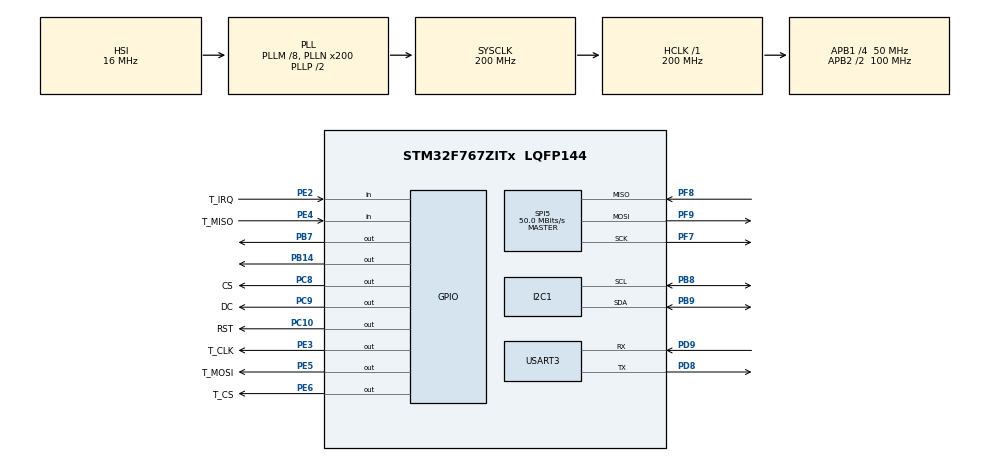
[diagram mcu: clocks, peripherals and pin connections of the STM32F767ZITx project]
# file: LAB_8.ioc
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CORTEX_M7.ART_ACCELERATOR_ENABLE=1
CORTEX_M7.CPU_DCache=Enabled
CORTEX_M7.CPU_ICache=Enabled
CORTEX_M7.MPU_Control=__NULL
CORTEX_M7.PREFETCH_ENABLE=1
CORTEX_M7.default_mode_Activation=1
I2C1.Timing=0x00C0EAFF
Mcu.Family=STM32F7
Mcu.Name=STM32F767ZITx
Mcu.Package=LQFP144
NVIC.PriorityGroup=NVIC_PRIORITYGROUP_2
PB14.Signal=GPIO_Output
PB7.Signal=GPIO_Output
PB8.Mode=I2C
PB8.Signal=I2C1_SCL
PB9.Mode=I2C
PB9.Signal=I2C1_SDA
PC10.GPIO_Label=RST
PC10.GPIO_Speed=GPIO_SPEED_FREQ_VERY_HIGH
PC10.Signal=GPIO_Output
PC8.GPIO_Label=CS
PC8.GPIO_Speed=GPIO_SPEED_FREQ_VERY_HIGH
PC8.PinState=GPIO_PIN_RESET
PC8.Signal=GPIO_Output
PC9.GPIO_Label=DC
PC9.GPIO_Speed=GPIO_SPEED_FREQ_VERY_HIGH
PC9.Signal=GPIO_Output
PD8.Mode=Asynchronous
PD8.Signal=USART3_TX
PD9.Mode=Asynchronous
PD9.Signal=USART3_RX
PE2.GPIO_Label=T_IRQ
PE2.Signal=GPIO_Input
PE3.GPIO_Label=T_CLK
PE3.GPIO_Speed=GPIO_SPEED_FREQ_VERY_HIGH
PE3.Signal=GPIO_Output
PE4.GPIO_Label=T_MISO
PE4.Signal=GPIO_Input
PE5.GPIO_Label=T_MOSI
PE5.GPIO_Speed=GPIO_SPEED_FREQ_VERY_HIGH
PE5.Signal=GPIO_Output
PE6.GPIO_Label=T_CS
PE6.GPIO_Speed=GPIO_SPEED_FREQ_VERY_HIGH
PE6.Signal=GPIO_Output
PF7.Mode=Full_Duplex_Master
PF7.Signal=SPI5_SCK
PF8.Mode=Full_Duplex_Master
PF8.Signal=SPI5_MISO
PF9.Mode=Full_Duplex_Master
PF9.Signal=SPI5_MOSI
PH0/OSC_IN.Mode=HSE-External-Oscillator
PH0/OSC_IN.Signal=RCC_OSC_IN
PH1/OSC_OUT.Mode=HSE-External-Oscillator
PH1/OSC_OUT.Signal=RCC_OSC_OUT
ProjectManager.HeapSize=0x200
ProjectManager.StackSize=0x400
ProjectManager.TargetToolchain=STM32CubeIDE
RCC.AHBFreq_Value=200000000
RCC.APB1CLKDivider=RCC_HCLK_DIV4
RCC.APB1Freq_Value=50000000
RCC.APB1TimFreq_Value=100000000
RCC.APB2CLKDivider=RCC_HCLK_DIV2
RCC.APB2Freq_Value=100000000
RCC.APB2TimFreq_Value=200000000
RCC.CortexFreq_Value=200000000
RCC.HCLKFreq_Value=200000000
RCC.HSE_VALUE=8000000
RCC.HSI_VALUE=16000000
RCC.LSE_VALUE=32768
RCC.PLLM=8
RCC.PLLN=200
RCC.PLLQ=9
RCC.SYSCLKFreq_VALUE=200000000
RCC.SYSCLKSource=RCC_SYSCLKSOURCE_PLLCLK
RCC.USBFreq_Value=44444444.44444445
RCC.VCOOutputFreq_Value=400000000
SPI5.CalculateBaudRate=50.0 MBits/s
SPI5.DataSize=SPI_DATASIZE_8BIT
SPI5.Direction=SPI_DIRECTION_2LINES
SPI5.Mode=SPI_MODE_MASTER
SPI5.NSSPMode=SPI_NSS_PULSE_DISABLE
SPI5.VirtualType=VM_MASTER
TIM1.ClockDivision=TIM_CLOCKDIVISION_DIV2
TIM1.Period=0
TIM1.Prescaler=10000
USART3.VirtualMode-Asynchronous=VM_ASYNC
VP_RNG_VS_RNG.Mode=RNG_Activate
VP_TIM1_VS_ClockSourceINT.Mode=Internal
board=custom

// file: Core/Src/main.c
/* USER CODE BEGIN Header */
/**
  ******************************************************************************
  * @file           : main.c
  * @brief          : Main program body
  ******************************************************************************
  * @attention
  *
  * Copyright (c) 2026 STMicroelectronics.
  * All rights reserved.
  *
  * This software is licensed under terms that can be found in the LICENSE file
  * in the root directory of this software component.
  * If no LICENSE file comes with this software, it is provided AS-IS.
  *
  ******************************************************************************
  */
/* USER CODE END Header */
#include "main.h"
#include "i2c.h"
#include "rng.h"
#include "spi.h"
#include "tim.h"
#include "usart.h"
#include "gpio.h"

/* USER CODE BEGIN Includes */
#include "stdio.h"
#include "string.h"
#include "ILI9341_GFX.h"
#include "ILI9341_STM32_Driver.h"
#include "ILI9341_Touchscreen.h"
/* USER CODE END Includes */

/* USER CODE BEGIN PD */
#define LD2_Pin GPIO_PIN_7
#define LD3_Pin GPIO_PIN_14

#define LIGHT_RED    0xFDB5
#define LIGHT_GREEN  0xC718
#define LIGHT_BLUE   0xAEDF
/* USER CODE END PD */

/* USER CODE BEGIN PV */
float h=30.0, t=40.0;
uint8_t step;
HAL_StatusTypeDef status;
uint8_t r_percent = 0, g_percent = 0, b_percent = 0;
const uint16_t profile[] = {
		0xff,0xff,0xff,0xff,0xff,0xff,0xff,0xff,0xff,0xff,0xff,0xff,0xff,0xff,0xff,0xff,0xff,0xff,0xff,0xff,0xff,0xff,0xff,0xff,0xff,0xff,0xff,0xff,0xff,0xff,0xff,0xff,0xff,0xff,0xff,0xff,0xff,0xff,0xff,0xff,0xff,0xff,0xff,0xff,0xff,0xff,0xff,0xff,0xff,0xff,0xff,0xff,0xff,0xff,0xff,0xff,0xff,0xff,0xff,0xff,0xff,0xff,0xff,0xff,0xff,0xff,0xff,0xff,0xff,0xff,0xff,0xff,0xff,0xff,0xff,0xff,0xff,0xff,0xff,0xff,0xff,0xff,0xff,0xff,0xff,0xff,0xff,0xff,0xff,0xff
		,0xff,0xff,0xff,0xff,0xff,0xff,0xff,0xff,0xff,0xff,0xff,0xff,0xff,0xff,0xff,0xff,0xff,0xff,0xff,0xff,0xff,0xff,0xff,0xff,0xff,0xff,0xff,0xff,0xff,0xff,0xff,0xff,0xff,0xff,0xff,0xff,0xff,0xff,0xff,0xff,0xff,0xff,0xff,0xff,0xff,0xff,0xff,0xff,0xff,0xff,0xff,0xff,0xff,0xff,0xff,0xff,0xff,0xff,0xff,0xff,0xff,0xff,0xff,0xff,0xff,0xff,0xff,0xff,0xff,0xff,0xff,0xff,0xff,0xff,0xff,0xff,0xff,0xff,0xff,0xff,0xff,0xff,0xff,0xff,0xff,0xff,0xff,0xff,0xff,0xff
		,0xff,0xff,0xff,0xff,0xff,0xff,0xff,0xff,0xff,0xff,0xff,0xff,0xff,0xff,0xff,0xff,0xff,0xff,0xff,0xff,0xff,0xff,0xff,0xff,0xff,0xff,0xff,0xff,0xff,0xff,0xff,0xff,0xff,0xff,0xff,0xff,0xff,0xff,0xff,0xff,0xff,0xff,0xff,0xff,0xff,0xff,0xff,0xff,0xff,0xff,0xff,0xff,0xff,0xff,0xff,0xff,0xff,0xff,0xff,0xff,0xff,0xff,0xff,0xff,0xff,0xff,0xff,0xff,0xff,0xff,0xff,0xff,0xff,0xff,0xff,0xff,0xff,0xff,0xff,0xff,0xff,0xff,0xff,0xff,0xff,0xff,0xff,0xff,0xff,0xff
		,0xff,0xff,0xff,0xff,0xff,0xff,0xff,0xff,0xff,0xff,0xff,0xff,0xff,0xff,0xff,0xff,0xff,0xff,0xff,0xff,0xff,0xff,0xff,0xff,0xff,0xff,0xff,0xff,0xff,0xff,0xff,0xff,0xff,0xff,0xff,0xff,0xff,0xff,0xff,0xff,0xff,0xff,0xff,0xff,0xff,0xff,0xff,0xff,0xff,0xff,0xff,0xff,0xff,0xff,0xff,0xff,0xff,0xff,0xff,0xff,0xff,0xff,0xff,0xff,0xff,0xff,0xff,0xff,0xff,0xff,0xff,0xff,0xff,0xff,0xff,0xff,0xff,0xff,0xff,0xff,0xff,0xff,0xff,0xff,0xff,0xff,0xff,0xff,0xff,0xff
		,0xff,0xff,0xff,0xff,0xff,0xff,0xff,0xff,0xff,0xff,0xff,0xff,0xff,0xff,0xff,0xff,0xff,0xff,0xff,0xff,0xff,0xff,0xff,0xff,0xff,0xff,0xff,0xff,0xff,0xff,0xff,0xff,0xff,0xff,0xff,0xff,0xff,0xff,0xff,0xff,0xff,0xff,0xff,0xff,0xff,0xff,0xff,0xff,0xff,0xff,0xff,0xff,0xff,0xff,0xff,0xff,0xff,0xff,0xff,0xff,0xff,0xff,0xff,0xff,0xff,0xff,0xff,0xff,0xff,0xff,0xff,0xff,0xff,0xff,0xff,0xff,0xff,0xff,0xff,0xff,0xff,0xff,0xff,0xff,0xff,0xff,0xff,0xff,0xff,0xff
		,0xff,0xff,0xff,0xff,0xff,0xff,0xff,0xff,0xff,0xff,0xff,0xff,0xff,0xff,0xff,0xff,0xff,0xff,0xff,0xff,0xff,0xff,0xff,0xff,0xff,0xff,0xff,0xff,0xff,0xff,0xff,0xff,0xff,0xff,0xff,0xff,0xff,0xff,0xff,0xff,0xff,0xff,0xff,0xff,0xff,0xff,0xff,0xff,0xff,0xff,0xff,0xff,0xff,0xff,0xff,0xff,0xff,0xff,0xff,0xff,0xff,0xff,0xff,0xff,0xff,0xff,0xff,0xff,0xff,0xff,0xff,0xff,0xff,0xff,0xff,0xff,0xff,0xff,0xff,0xff,0xff,0xff,0xff,0xff,0xff,0xff,0xff,0xff,0xff,0xff
		,0xff,0xff,0xff,0xff,0xff,0xff,0xff,0xff,0xff,0xff,0xff,0xff,0xff,0xff,0xff,0xff,0xff,0xff,0xff,0xff,0xff,0xff,0xff,0xff,0xff,0xff,0xff,0xff,0xff,0xff,0xff,0xff,0xff,0xff,0xff,0xff,0xff,0xff,0xff,0xff,0xff,0xff,0xff,0xff,0xff,0xff,0xff,0xff,0xff,0xff,0xff,0xff,0xff,0xff,0xff,0xff,0xff,0xff,0xff,0xff,0xff,0xff,0xff,0xff,0xff,0xff,0xff,0xff,0xff,0xff,0xff,0xff,0xff,0xff,0xff,0xff,0xff,0xff,0xff,0xff,0xff,0xff,0xff,0xff,0xff,0xff,0xff,0xff,0xff,0xff
		,0xff,0xff,0xff,0xff,0xff,0xff,0xff,0xff,0xff,0xff,0xff,0xff,0xff,0xff,0xff,0xff,0xff,0xff,0xff,0xff,0xff,0xff,0xff,0xff,0xff,0xff,0xff,0xff,0xff,0xff,0xff,0xff,0xff,0xff,0xff,0xff,0xff,0xff,0xff,0xff,0xff,0xff,0xff,0xff,0xff,0xff,0xff,0xff,0xff,0xff,0xff,0xff,0xff,0xff,0xff,0xff,0xff,0xff,0xff,0xff,0xff,0xff,0xff,0xff,0xff,0xff,0xff,0xff,0xff,0xff,0xff,0xff,0xff,0xff,0xff,0xff,0xff,0xff,0xff,0xff,0xff,0xff,0xff,0xff,0xff,0xff,0xff,0xff,0xff,0xff
		,0xff,0xff,0xff,0xff,0xff,0xff,0xff,0xff,0xff,0xff,0xff,0xff,0xff,0xff,0xff,0xff,0xff,0xff,0xff,0xff,0xff,0xff,0xff,0xff,0xff,0xff,0xff,0xff,0xff,0xff,0xff,0xff,0xff,0xff,0xff,0xff,0xff,0xff,0xff,0xff,0xff,0xff,0xff,0xff,0xdb,0xdb,0xff,0xff,0xff,0xff,0xff,0xdb,0xff,0xff,0xff,0xff,0xff,0xff,0xff,0xff,0xff,0xff,0xff,0xff,0xff,0xff,0xff,0xff,0xff,0xff,0xff,0xff,0xff,0xff,0xff,0xff,0xff,0xff,0xff,0xff,0xff,0xff,0xff,0xff,0xff,0xff,0xff,0xff,0xff,0xff
		,0xff,0xff,0xff,0xff,0xff,0xff,0xff,0xff,0xff,0xff,0xff,0xff,0xff,0xff,0xff,0xff,0xff,0xff,0xff,0xff,0xff,0xff,0xff,0xff,0xff,0xff,0xff,0xff,0xff,0xff,0xff,0xff,0xff,0xff,0xff,0xff,0xff,0xff,0xff,0xff,0xdb,0x92,0x49,0x25,0x25,0x49,0x49,0x6d,0x49,0x24,0x25,0x24,0x49,0xff,0xff,0xff,0xff,0xff,0xff,0xff,0xff,0xff,0xff,0xff,0xff,0xff,0xff,0xff,0xff,0xff,0xff,0xff,0xff,0xff,0xff,0xff,0xff,0xff,0xff,0xff,0xff,0xff,0xff,0xff,0xff,0xff,0xff,0xff,0xff,0xff
		,0xff,0xff,0xff,0xff,0xff,0xff,0xff,0xff,0xff,0xff,0xff,0xff,0xff,0xff,0xff,0xff,0xff,0xff,0xff,0xff,0xff,0xff,0xff,0xff,0xff,0xff,0xff,0xff,0xff,0xff,0xff,0xff,0xff,0xff,0xff,0xff,0xff,0xb6,0x72,0x49,0x24,0x00,0x00,0x00,0x00,0x00,0x00,0x00,0x00,0x00,0x00,0x00,0x00,0x49,0xdb,0xff,0xff,0xff,0xff,0xff,0xff,0xff,0xff,0xff,0xff,0xff,0xff,0xff,0xff,0xff,0xff,0xff,0xff,0xff,0xff,0xff,0xff,0xff,0xff,0xff,0xff,0xff,0xff,0xff,0xff,0xff,0xff,0xff,0xff,0xff
		,0xff,0xff,0xff,0xff,0xff,0xff,0xff,0xff,0xff,0xff,0xff,0xff,0xff,0xff,0xff,0xff,0xff,0xff,0xff,0xff,0xff,0xff,0xff,0xff,0xff,0xff,0xff,0xff,0xff,0xff,0xff,0xff,0xff,0xff,0xff,0xb6,0x29,0x00,0x04,0x00,0x00,0x00,0x00,0x00,0x00,0x00,0x00,0x00,0x00,0x00,0x00,0x00,0x00,0x00,0x6d,0xdb,0xff,0xff,0xff,0xff,0xff,0xff,0xff,0xff,0xff,0xff,0xff,0xff,0xff,0xff,0xff,0xff,0xff,0xff,0xff,0xff,0xff,0xff,0xff,0xff,0xff,0xff,0xff,0xff,0xff,0xff,0xff,0xff,0xff,0xff
		,0xff,0xff,0xff,0xff,0xff,0xff,0xff,0xff,0xff,0xff,0xff,0xff,0xff,0xff,0xff,0xff,0xff,0xff,0xff,0xff,0xff,0xff,0xff,0xff,0xff,0xff,0xff,0xff,0xff,0xff,0xff,0xff,0xff,0xb6,0x49,0x24,0x00,0x00,0x00,0x00,0x00,0x00,0x00,0x00,0x00,0x00,0x00,0x00,0x00,0x00,0x00,0x00,0x00,0x00,0x00,0x49,0x49,0x6e,0xb6,0xff,0xff,0xff,0xff,0xff,0xff,0xff,0xff,0xff,0xff,0xff,0xff,0xff,0xff,0xff,0xff,0xff,0xff,0xff,0xff,0xff,0xff,0xff,0xff,0xff,0xff,0xff,0xff,0xff,0xff,0xff
		,0xff,0xff,0xff,0xff,0xff,0xff,0xff,0xff,0xff,0xff,0xff,0xff,0xff,0xff,0xff,0xff,0xff,0xff,0xff,0xff,0xff,0xff,0xff,0xff,0xff,0xff,0xff,0xff,0xff,0xff,0xff,0xff,0x6d,0x24,0x00,0x00,0x00,0x00,0x00,0x00,0x00,0x00,0x00,0x00,0x00,0x00,0x00,0x00,0x00,0x00,0x00,0x00,0x00,0x00,0x00,0x00,0x00,0x00,0x25,0x49,0xdb,0xff,0xff,0xff,0xff,0xff,0xff,0xff,0xff,0xff,0xff,0xff,0xff,0xff,0xff,0xff,0xff,0xff,0xff,0xff,0xff,0xff,0xff,0xff,0xff,0xff,0xff,0xff,0xff,0xff
		,0xff,0xff,0xff,0xff,0xff,0xff,0xff,0xff,0xff,0xff,0xff,0xff,0xff,0xff,0xff,0xff,0xff,0xff,0xff,0xff,0xff,0xff,0xff,0xff,0xff,0xff,0xff,0xff,0xff,0xff,0xff,0x92,0x24,0x00,0x00,0x00,0x00,0x00,0x00,0x00,0x00,0x00,0x00,0x00,0x00,0x00,0x00,0x00,0x00,0x00,0x00,0x00,0x00,0x00,0x00,0x00,0x00,0x00,0x00,0x04,0x24,0x92,0xff,0xff,0xff,0xff,0xff,0xff,0xff,0xff,0xff,0xff,0xff,0xff,0xff,0xff,0xff,0xff,0xff,0xff,0xff,0xff,0xff,0xff,0xff,0xff,0xff,0xff,0xff,0xff
		,0xff,0xff,0xff,0xff,0xff,0xff,0xff,0xff,0xff,0xff,0xff,0xff,0xff,0xff,0xff,0xff,0xff,0xff,0xff,0xff,0xff,0xff,0xff,0xff,0xff,0xff,0xff,0xff,0xff,0xdb,0x49,0x24,0x00,0x00,0x00,0x00,0x00,0x00,0x00,0x00,0x00,0x00,0x00,0x00,0x00,0x00,0x00,0x00,0x00,0x00,0x00,0x00,0x00,0x00,0x00,0x00,0x00,0x00,0x00,0x00,0x00,0x04,0x49,0xdb,0xff,0xff,0xff,0xff,0xff,0xff,0xff,0xff,0xff,0xff,0xff,0xff,0xff,0xff,0xff,0xff,0xff,0xff,0xff,0xff,0xff,0xff,0xff,0xff,0xff,0xff
		,0xff,0xff,0xff,0xff,0xff,0xff,0xff,0xff,0xff,0xff,0xff,0xff,0xff,0xff,0xff,0xff,0xff,0xff,0xff,0xff,0xff,0xff,0xff,0xff,0xff,0xff,0xff,0xff,0xb6,0x29,0x24,0x00,0x00,0x00,0x00,0x00,0x00,0x00,0x00,0x00,0x00,0x00,0x00,0x00,0x00,0x00,0x00,0x00,0x00,0x00,0x00,0x00,0x00,0x00,0x00,0x00,0x00,0x00,0x00,0x00,0x00,0x00,0x04,0x49,0xbb,0xff,0xff,0xff,0xff,0xff,0xff,0xff,0xff,0xff,0xff,0xff,0xff,0xff,0xff,0xff,0xff,0xff,0xff,0xff,0xff,0xff,0xff,0xff,0xff,0xff
		,0xff,0xff,0xff,0xff,0xff,0xff,0xff,0xff,0xff,0xff,0xff,0xff,0xff,0xff,0xff,0xff,0xff,0xff,0xff,0xff,0xff,0xff,0xff,0xff,0xff,0xff,0xff,0xb7,0x25,0x24,0x25,0x00,0x00,0x00,0x00,0x00,0x00,0x00,0x00,0x00,0x00,0x00,0x00,0x00,0x00,0x00,0x00,0x00,0x00,0x00,0x00,0x00,0x00,0x00,0x00,0x00,0x00,0x00,0x00,0x00,0x00,0x00,0x00,0x24,0x6e,0xb7,0xff,0xff,0xff,0xff,0xff,0xff,0xff,0xff,0xff,0xff,0xff,0xff,0xff,0xff,0xff,0xff,0xff,0xff,0xff,0xff,0xff,0xff,0xff,0xff
		,0xff,0xff,0xff,0xff,0xff,0xff,0xff,0xff,0xff,0xff,0xff,0xff,0xff,0xff,0xff,0xff,0xff,0xff,0xff,0xff,0xff,0xff,0xff,0xff,0xff,0xff,0xff,0x49,0x24,0x25,0x00,0x00,0x00,0x00,0x00,0x24,0x24,0x00,0x00,0x00,0x00,0x00,0x00,0x00,0x00,0x00,0x00,0x00,0x00,0x00,0x00,0x00,0x00,0x00,0x00,0x00,0x00,0x00,0x00,0x00,0x00,0x00,0x00,0x00,0x24,0x29,0xdb,0xff,0xff,0xff,0xff,0xff,0xff,0xff,0xff,0xff,0xff,0xff,0xff,0xff,0xff,0xff,0xff,0xff,0xff,0xff,0xff,0xff,0xff,0xff
		,0xff,0xff,0xff,0xff,0xff,0xff,0xff,0xff,0xff,0xff,0xff,0xff,0xff,0xff,0xff,0xff,0xff,0xff,0xff,0xff,0xff,0xff,0xff,0xff,0xff,0xff,0x92,0x24,0x04,0x00,0x00,0x00,0x00,0x00,0x24,0x24,0x04,0x00,0x00,0x00,0x00,0x00,0x00,0x00,0x00,0x00,0x00,0x00,0x00,0x00,0x00,0x00,0x00,0x00,0x00,0x00,0x00,0x00,0x00,0x00,0x00,0x00,0x00,0x00,0x00,0x00,0x25,0xb7,0xff,0xff,0xff,0xff,0xff,0xff,0xff,0xff,0xff,0xff,0xff,0xff,0xff,0xff,0xff,0xff,0xff,0xff,0xff,0xff,0xff,0xff
		,0xff,0xff,0xff,0xff,0xff,0xff,0xff,0xff,0xff,0xff,0xff,0xff,0xff,0xff,0xff,0xff,0xff,0xff,0xff,0xff,0xff,0xff,0xff,0xff,0xff,0xb6,0x25,0x00,0x00,0x24,0x24,0x00,0x00,0x24,0x25,0x24,0x04,0x24,0x25,0x24,0x04,0x00,0x00,0x00,0x00,0x00,0x00,0x00,0x00,0x00,0x00,0x00,0x00,0x00,0x00,0x00,0x00,0x00,0x00,0x00,0x00,0x00,0x00,0x00,0x00,0x00,0x00,0x24,0xdb,0xff,0xff,0xff,0xff,0xff,0xff,0xff,0xff,0xff,0xff,0xff,0xff,0xff,0xff,0xff,0xff,0xff,0xff,0xff,0xff,0xff
		,0xff,0xff,0xff,0xff,0xff,0xff,0xff,0xff,0xff,0xff,0xff,0xff,0xff,0xff,0xff,0xff,0xff,0xff,0xff,0xff,0xff,0xff,0xff,0xff,0xdb,0x29,0x00,0x00,0x25,0x25,0x25,0x24,0x25,0x25,0x25,0x25,0x25,0x25,0x25,0x25,0x00,0x00,0x00,0x00,0x00,0x00,0x00,0x00,0x04,0x00,0x00,0x00,0x00,0x00,0x00,0x00,0x00,0x00,0x00,0x00,0x00,0x00,0x00,0x00,0x00,0x00,0x00,0x00,0x49,0xff,0xff,0xff,0xff,0xff,0xff,0xff,0xff,0xff,0xff,0xff,0xff,0xff,0xff,0xff,0xff,0xff,0xff,0xff,0xff,0xff
		,0xff,0xff,0xff,0xff,0xff,0xff,0xff,0xff,0xff,0xff,0xff,0xff,0xff,0xff,0xff,0xff,0xff,0xff,0xff,0xff,0xff,0xff,0xff,0xff,0x6d,0x04,0x00,0x04,0x25,0x25,0x25,0x04,0x04,0x04,0x25,0x25,0x04,0x00,0x00,0x04,0x24,0x25,0x00,0x00,0x00,0x00,0x00,0x00,0x00,0x04,0x00,0x00,0x00,0x00,0x00,0x00,0x00,0x00,0x00,0x00,0x00,0x00,0x00,0x00,0x00,0x00,0x00,0x00,0x00,0x6e,0xff,0xff,0xff,0xff,0xff,0xff,0xff,0xff,0xff,0xff,0xff,0xff,0xff,0xff,0xff,0xff,0xff,0xff,0xff,0xff
		,0xff,0xff,0xff,0xff,0xff,0xff,0xff,0xff,0xff,0xff,0xff,0xff,0xff,0xff,0xff,0xff,0xff,0xff,0xff,0xff,0xff,0xff,0xff,0x92,0x04,0x00,0x04,0x04,0x00,0x00,0x00,0x00,0x00,0x24,0x00,0x00,0x00,0x04,0x24,0x24,0x25,0x25,0x24,0x00,0x00,0x00,0x00,0x00,0x00,0x00,0x00,0x00,0x00,0x20,0x00,0x00,0x00,0x00,0x00,0x00,0x00,0x00,0x00,0x00,0x00,0x00,0x00,0x04,0x00,0x20,0xdb,0xff,0xff,0xff,0xff,0xff,0xff,0xff,0xff,0xff,0xff,0xff,0xff,0xff,0xff,0xff,0xff,0xff,0xff,0xff
		,0xff,0xff,0xff,0xff,0xff,0xff,0xff,0xff,0xff,0xff,0xff,0xff,0xff,0xff,0xff,0xff,0xff,0xff,0xff,0xff,0xff,0xff,0xdf,0x29,0x00,0x00,0x00,0x00,0x00,0x00,0x00,0x00,0x00,0x00,0x00,0x24,0x04,0x24,0x24,0x24,0x00,0x24,0x24,0x00,0x00,0x00,0x00,0x00,0x04,0x00,0x00,0x24,0x24,0x00,0x00,0x00,0x00,0x00,0x00,0x00,0x00,0x00,0x00,0x00,0x00,0x00,0x04,0x24,0x04,0x00,0x49,0xff,0xff,0xff,0xff,0xff,0xff,0xff,0xff,0xff,0xff,0xff,0xff,0xff,0xff,0xff,0xff,0xff,0xff,0xff
		,0xff,0xff,0xff,0xff,0xff,0xff,0xff,0xff,0xff,0xff,0xff,0xff,0xff,0xff,0xff,0xff,0xff,0xff,0xff,0xff,0xff,0xff,0x92,0x00,0x00,0x00,0x00,0x00,0x00,0x00,0x00,0x00,0x00,0x00,0x04,0x25,0x24,0x25,0x25,0x24,0x04,0x00,0x00,0x00,0x00,0x00,0x00,0x24,0x00,0x24,0x24,0x00,0x00,0x00,0x00,0x00,0x00,0x00,0x00,0x00,0x00,0x00,0x00,0x00,0x00,0x00,0x25,0x04,0x00,0x00,0x24,0xdb,0xff,0xff,0xff,0xff,0xff,0xff,0xff,0xff,0xff,0xff,0xff,0xff,0xff,0xff,0xff,0xff,0xff,0xff
		,0xff,0xff,0xff,0xff,0xff,0xff,0xff,0xff,0xff,0xff,0xff,0xff,0xff,0xff,0xff,0xff,0xff,0xff,0xff,0xff,0xff,0xdb,0x25,0x00,0x04,0x00,0x00,0x00,0x00,0x00,0x00,0x00,0x00,0x04,0x25,0x24,0x00,0x24,0x25,0x25,0x25,0x04,0x04,0x00,0x00,0x00,0x24,0x25,0x25,0x24,0x00,0x00,0x00,0x00,0x00,0x20,0x00,0x00,0x00,0x00,0x00,0x00,0x00,0x00,0x00,0x00,0x25,0x04,0x00,0x00,0x00,0x92,0xff,0xff,0xff,0xff,0xff,0xff,0xff,0xff,0xff,0xff,0xff,0xff,0xff,0xff,0xff,0xff,0xff,0xff
		,0xff,0xff,0xff,0xff,0xff,0xff,0xff,0xff,0xff,0xff,0xff,0xff,0xff,0xff,0xff,0xff,0xff,0xff,0xff,0xff,0xff,0x6e,0x00,0x00,0x04,0x00,0x00,0x00,0x00,0x00,0x00,0x00,0x04,0x24,0x04,0x00,0x00,0x04,0x24,0x25,0x25,0x24,0x04,0x04,0x00,0x24,0x25,0x00,0x00,0x00,0x00,0x24,0x00,0x00,0x20,0x00,0x00,0x00,0x00,0x00,0x00,0x00,0x04,0x00,0x24,0x00,0x04,0x00,0x00,0x00,0x00,0x49,0xff,0xff,0xff,0xff,0xff,0xff,0xff,0xff,0xff,0xff,0xff,0xff,0xff,0xff,0xff,0xff,0xff,0xff
		,0xff,0xff,0xff,0xff,0xff,0xff,0xff,0xff,0xff,0xff,0xff,0xff,0xff,0xff,0xff,0xff,0xff,0xff,0xff,0xff,0xdb,0x24,0x00,0x00,0x00,0x00,0x00,0x00,0x00,0x00,0x00,0x00,0x00,0x00,0x20,0x00,0x00,0x00,0x24,0x25,0x25,0x25,0x25,0x25,0x25,0x25,0x25,0x20,0x20,0x20,0x00,0x24,0x24,0x24,0x20,0x20,0x00,0x00,0x00,0x00,0x00,0x00,0x24,0x00,0x04,0x04,0x04,0x04,0x00,0x25,0x04,0x24,0xdb,0xff,0xff,0xff,0xff,0xff,0xff,0xff,0xff,0xff,0xff,0xff,0xff,0xff,0xff,0xff,0xff,0xff
		,0xff,0xff,0xff,0xff,0xff,0xff,0xff,0xff,0xff,0xff,0xff,0xff,0xff,0xff,0xff,0xff,0xff,0xff,0xff,0xff,0xb6,0x00,0x00,0x00,0x00,0x00,0x00,0x00,0x00,0x00,0x00,0x00,0x00,0x00,0x00,0x20,0x00,0x00,0x00,0x00,0x25,0x25,0x25,0x20,0x25,0x25,0x45,0x24,0x24,0x24,0x20,0x24,0x24,0x00,0x20,0x00,0x00,0x20,0x00,0x00,0x00,0x00,0x04,0x00,0x00,0x00,0x05,0x00,0x00,0x00,0x25,0x00,0xb7,0xff,0xff,0xff,0xff,0xff,0xff,0xff,0xff,0xff,0xff,0xff,0xff,0xff,0xff,0xff,0xff,0xff
		,0xff,0xff,0xff,0xff,0xff,0xff,0xff,0xff,0xff,0xff,0xff,0xff,0xff,0xff,0xff,0xff,0xff,0xff,0xff,0xff,0x92,0x00,0x00,0x00,0x00,0x00,0x00,0x00,0x00,0x00,0x00,0x00,0x00,0x20,0x20,0x24,0x00,0x00,0x00,0x00,0x20,0x24,0x24,0x25,0x45,0x69,0x69,0x45,0x45,0x24,0x24,0x24,0x20,0x20,0x20,0x00,0x00,0x20,0x20,0x20,0x24,0x00,0x00,0x04,0x00,0x00,0x05,0x00,0x00,0x00,0x04,0x05,0x92,0xff,0xff,0xff,0xff,0xff,0xff,0xff,0xff,0xff,0xff,0xff,0xff,0xff,0xff,0xff,0xff,0xff
		,0xff,0xff,0xff,0xff,0xff,0xff,0xff,0xff,0xff,0xff,0xff,0xff,0xff,0xff,0xff,0xff,0xff,0xff,0xff,0xff,0x6e,0x00,0x00,0x00,0x00,0x00,0x00,0x00,0x00,0x00,0x00,0x20,0x20,0x20,0x24,0x20,0x00,0x00,0x24,0x24,0x44,0x25,0x25,0x44,0x69,0x69,0x45,0x45,0x45,0x45,0x24,0x24,0x24,0x24,0x20,0x00,0x20,0x24,0x44,0x24,0x45,0x20,0x00,0x00,0x04,0x05,0x25,0x00,0x00,0x00,0x00,0x25,0x6e,0xff,0xff,0xff,0xff,0xff,0xff,0xff,0xff,0xff,0xff,0xff,0xff,0xff,0xff,0xff,0xff,0xff
		,0xff,0xff,0xff,0xff,0xff,0xff,0xff,0xff,0xff,0xff,0xff,0xff,0xff,0xff,0xff,0xff,0xff,0xff,0xff,0xff,0x6d,0x00,0x00,0x00,0x00,0x00,0x00,0x00,0x00,0x00,0x20,0x24,0x20,0x24,0x20,0x00,0x24,0x45,0x65,0x69,0x69,0x45,0x69,0x69,0x69,0x45,0x45,0x69,0x45,0x45,0x25,0x45,0x25,0x24,0x20,0x20,0x24,0x44,0x44,0x25,0x69,0x24,0x00,0x00,0x04,0x25,0x25,0x00,0x00,0x04,0x00,0x25,0x92,0xff,0xff,0xff,0xff,0xff,0xff,0xff,0xff,0xff,0xff,0xff,0xff,0xff,0xff,0xff,0xff,0xff
		,0xff,0xff,0xff,0xff,0xff,0xff,0xff,0xff,0xff,0xff,0xff,0xff,0xff,0xff,0xff,0xff,0xff,0xff,0xff,0xff,0x49,0x00,0x00,0x00,0x00,0x00,0x00,0x00,0x20,0x00,0x44,0x20,0x20,0x20,0x00,0x24,0x45,0x69,0x8d,0x89,0x44,0x89,0x8d,0x89,0x69,0x69,0x69,0x8d,0x69,0x49,0x25,0x25,0x25,0x24,0x20,0x24,0x45,0x45,0x45,0x45,0x69,0x45,0x20,0x00,0x04,0x04,0x25,0x00,0x00,0x04,0x00,0x05,0x72,0xff,0xff,0xff,0xff,0xff,0xff,0xff,0xff,0xff,0xff,0xff,0xff,0xff,0xff,0xff,0xff,0xff
		,0xff,0xff,0xff,0xff,0xff,0xff,0xff,0xff,0xff,0xff,0xff,0xff,0xff,0xff,0xff,0xff,0xff,0xff,0xff,0xff,0x24,0x00,0x00,0x00,0x00,0x00,0x00,0x20,0x20,0x44,0x24,0x00,0x20,0x00,0x24,0x45,0x69,0x8d,0x89,0x89,0x8d,0xad,0x8d,0x8d,0xad,0x8d,0x8d,0x89,0x69,0x45,0x24,0x45,0x45,0x24,0x24,0x44,0x69,0x69,0x69,0x69,0x69,0x45,0x20,0x00,0x25,0x00,0x25,0x00,0x00,0x04,0x04,0x25,0x6e,0xff,0xff,0xff,0xff,0xff,0xff,0xff,0xff,0xff,0xff,0xff,0xff,0xff,0xff,0xff,0xff,0xff
		,0xff,0xff,0xff,0xff,0xff,0xff,0xff,0xff,0xff,0xff,0xff,0xff,0xff,0xff,0xff,0xff,0xff,0xff,0xff,0xff,0x24,0x00,0x00,0x00,0x00,0x00,0x00,0x44,0x20,0x44,0x00,0x44,0x20,0x24,0x45,0x69,0x89,0x8d,0x8d,0xb2,0xae,0xb2,0xb2,0xae,0xb2,0xb2,0xae,0x89,0x45,0x45,0x69,0x45,0x45,0x45,0x45,0x45,0x89,0x89,0x69,0x69,0x69,0x69,0x24,0x00,0x25,0x00,0x25,0x04,0x00,0x05,0x04,0x25,0x6e,0xff,0xff,0xff,0xff,0xff,0xff,0xff,0xff,0xff,0xff,0xff,0xff,0xff,0xff,0xff,0xff,0xff
		,0xff,0xff,0xff,0xff,0xff,0xff,0xff,0xff,0xff,0xff,0xff,0xff,0xff,0xff,0xff,0xff,0xff,0xff,0xff,0xff,0x24,0x00,0x00,0x00,0x00,0x00,0x00,0x44,0x24,0x24,0x24,0x44,0x24,0x44,0x65,0x89,0xad,0xad,0xb2,0xd2,0xd2,0xd2,0xd2,0xb2,0xb2,0xb2,0x8d,0x69,0x69,0x45,0x69,0x45,0x69,0x69,0x69,0x89,0x89,0x8d,0x69,0x69,0x89,0x89,0x44,0x20,0x25,0x04,0x04,0x05,0x00,0x05,0x25,0x25,0x6e,0xff,0xff,0xff,0xff,0xff,0xff,0xff,0xff,0xff,0xff,0xff,0xff,0xff,0xff,0xff,0xff,0xff
		,0xff,0xff,0xff,0xff,0xff,0xff,0xff,0xff,0xff,0xff,0xff,0xff,0xff,0xff,0xff,0xff,0xff,0xff,0xff,0xff,0x25,0x00,0x00,0x00,0x00,0x00,0x20,0x69,0x44,0x20,0x44,0x44,0x69,0x65,0x89,0xad,0xae,0xb2,0xd2,0xd2,0xd6,0xd2,0xd2,0xb2,0xd2,0xad,0x8d,0xad,0x45,0x69,0x69,0x89,0x69,0x69,0x69,0x8d,0x89,0x8d,0x69,0x89,0x8d,0x89,0x44,0x24,0x24,0x00,0x04,0x25,0x05,0x04,0x04,0x05,0x92,0xff,0xff,0xff,0xff,0xff,0xff,0xff,0xff,0xff,0xff,0xff,0xff,0xff,0xff,0xff,0xff,0xff
		,0xff,0xff,0xff,0xff,0xff,0xff,0xff,0xff,0xff,0xff,0xff,0xff,0xff,0xff,0xff,0xff,0xff,0xff,0xff,0xff,0x49,0x00,0x00,0x00,0x00,0x00,0x20,0x65,0x69,0x44,0x65,0x69,0x69,0x89,0xad,0xb2,0xd2,0xd2,0xd6,0xd6,0xd6,0xd6,0xd2,0xd2,0xb2,0xae,0xb2,0x8d,0x44,0x69,0x89,0x8d,0x89,0x89,0x8d,0xad,0x8d,0x8d,0x69,0x89,0x8d,0x8d,0x69,0x24,0x00,0x00,0x04,0x25,0x25,0x00,0x04,0x00,0x92,0xff,0xff,0xff,0xff,0xff,0xff,0xff,0xff,0xff,0xff,0xff,0xff,0xff,0xff,0xff,0xff,0xff
		,0xff,0xff,0xff,0xff,0xff,0xff,0xff,0xff,0xff,0xff,0xff,0xff,0xff,0xff,0xff,0xff,0xff,0xff,0xff,0xff,0x6d,0x00,0x00,0x00,0x00,0x00,0x24,0x69,0x89,0x44,0x89,0x8d,0x69,0xad,0xb2,0xd2,0xd2,0xd6,0xd6,0xd6,0xd6,0xd6,0xd6,0xd6,0xae,0xd2,0xd2,0x69,0x69,0x8d,0x8d,0x89,0x89,0x8d,0xae,0xad,0x8d,0x89,0x89,0x8d,0xad,0xad,0x65,0x24,0x00,0x00,0x04,0x25,0x25,0x00,0x00,0x00,0xb6,0xff,0xff,0xff,0xff,0xff,0xff,0xff,0xff,0xff,0xff,0xff,0xff,0xff,0xff,0xff,0xff,0xff
		,0xff,0xff,0xff,0xff,0xff,0xff,0xff,0xff,0xff,0xff,0xff,0xff,0xff,0xff,0xff,0xff,0xff,0xff,0xff,0xff,0x92,0x00,0x00,0x00,0x00,0x00,0x44,0x89,0x89,0x44,0xad,0x69,0x8d,0xb2,0xd2,0xd6,0xd6,0xd6,0xd6,0xd6,0xd6,0xd6,0xd6,0xd2,0xb2,0xd2,0xb2,0x69,0xae,0xb2,0xae,0x89,0x8e,0xb2,0xae,0x8e,0x8d,0x69,0x8d,0xad,0xad,0xad,0x69,0x44,0x20,0x00,0x24,0x04,0x04,0x00,0x00,0x24,0xff,0xff,0xff,0xff,0xff,0xff,0xff,0xff,0xff,0xff,0xff,0xff,0xff,0xff,0xff,0xff,0xff,0xff
		,0xff,0xff,0xff,0xff,0xff,0xff,0xff,0xff,0xff,0xff,0xff,0xff,0xff,0xff,0xff,0xff,0xff,0xff,0xff,0xff,0xff,0x49,0x00,0x00,0x00,0x24,0x44,0x89,0x8d,0x69,0x8d,0x45,0x8d,0xb2,0xb2,0xd6,0xd6,0xd6,0xd6,0xd6,0xd6,0xd6,0xd6,0xd2,0xd2,0xd2,0x8d,0xad,0xb2,0xae,0xae,0x8e,0x8e,0x8e,0x8d,0x69,0x69,0x45,0x69,0xad,0xad,0xad,0x89,0x69,0x44,0x20,0x24,0x24,0x00,0x00,0x00,0x6d,0xff,0xff,0xff,0xff,0xff,0xff,0xff,0xff,0xff,0xff,0xff,0xff,0xff,0xff,0xff,0xff,0xff,0xff
		,0xff,0xff,0xff,0xff,0xff,0xff,0xff,0xff,0xff,0xff,0xff,0xff,0xff,0xff,0xff,0xff,0xff,0xff,0xff,0xff,0xff,0xdb,0x25,0x00,0x20,0x24,0x69,0x8d,0xad,0x69,0x69,0x45,0x69,0x8d,0x8e,0xb2,0xb2,0xd6,0xd6,0xd6,0xd6,0xd6,0xd6,0xd2,0xd6,0xd2,0xae,0xb2,0xb2,0xae,0x8d,0x69,0x49,0x49,0x49,0x69,0x69,0x45,0x45,0x69,0xad,0xad,0x8d,0x89,0x45,0x24,0x24,0x20,0x00,0x00,0x00,0xb7,0xff,0xff,0xff,0xff,0xff,0xff,0xff,0xff,0xff,0xff,0xff,0xff,0xff,0xff,0xff,0xff,0xff,0xff
		,0xff,0xff,0xff,0xff,0xff,0xff,0xff,0xff,0xff,0xff,0xff,0xff,0xff,0xff,0xff,0xff,0xff,0xff,0xff,0xff,0xff,0xff,0x72,0x00,0x20,0x44,0x8d,0xad,0xad,0x49,0x44,0x45,0x69,0x69,0x69,0x69,0x69,0x8e,0xb2,0xd2,0xd6,0xd6,0xd6,0xd6,0xd6,0xd6,0xb2,0xb2,0xae,0x89,0x45,0x45,0x69,0x69,0x8e,0xb2,0xae,0x8d,0x8d,0x69,0x89,0xad,0xad,0xad,0x69,0x44,0x24,0x00,0x00,0x00,0x49,0xff,0xff,0xff,0xff,0xff,0xff,0xff,0xff,0xff,0xff,0xff,0xff,0xff,0xff,0xff,0xff,0xff,0xff,0xff
		,0xff,0xff,0xff,0xff,0xff,0xff,0xff,0xff,0xff,0xff,0xff,0xff,0xff,0xff,0xff,0xff,0xff,0xff,0xff,0xff,0xff,0xff,0xdb,0x24,0x24,0x45,0x8d,0xad,0x89,0x69,0x8d,0x8e,0xb2,0xb2,0x8e,0x69,0x69,0x69,0x69,0x8d,0xb2,0xd2,0xd6,0xd6,0xd6,0xd6,0xb2,0xb2,0xae,0x8d,0x8d,0x8e,0xb2,0xd6,0xd6,0xd6,0xd2,0xb2,0xb2,0xae,0x8d,0xad,0xad,0xad,0x8d,0x45,0x24,0x20,0x00,0x04,0x92,0xff,0xff,0xff,0xff,0xff,0xff,0xff,0xff,0xff,0xff,0xff,0xff,0xff,0xff,0xff,0xff,0xff,0xff,0xff
		,0xff,0xff,0xff,0xff,0xff,0xff,0xff,0xff,0xff,0xff,0xff,0xff,0xff,0xff,0xff,0xff,0xff,0xff,0xff,0xff,0xff,0xff,0xff,0x49,0x24,0x45,0xad,0xad,0xad,0xad,0xb2,0xb2,0xd6,0xd6,0xd6,0xd6,0xb2,0xae,0x8d,0x8d,0xae,0xb2,0xd6,0xd6,0xd6,0xd6,0xd2,0xae,0xae,0xb2,0xb2,0xd2,0xd6,0xd6,0xd7,0xd6,0xd6,0xd2,0xd2,0xb2,0xae,0xb2,0xad,0xad,0xad,0x69,0x24,0x20,0x00,0x24,0xdb,0xff,0xff,0xff,0xff,0xff,0xff,0xff,0xff,0xff,0xff,0xff,0xff,0xff,0xff,0xff,0xff,0xff,0xff,0xff
		,0xff,0xff,0xff,0xff,0xff,0xff,0xff,0xff,0xff,0xff,0xff,0xff,0xff,0xff,0xff,0xff,0xff,0xff,0xff,0xff,0xff,0xff,0xff,0x6d,0x24,0x45,0xad,0xad,0xb2,0xb2,0xb2,0xd2,0xd6,0xd6,0xd6,0xd6,0xd6,0xd2,0xb2,0xb2,0xb2,0xb2,0xd2,0xd6,0xd6,0xd6,0xd2,0xb2,0xb2,0xb2,0xd2,0xd2,0xd2,0xd6,0xd6,0xd2,0xd2,0xd2,0xd2,0xb2,0xb2,0xb2,0xb2,0xad,0xad,0x69,0x24,0x24,0x00,0x45,0xb2,0xd6,0xdb,0xff,0xff,0xff,0xff,0xff,0xff,0xff,0xff,0xff,0xff,0xff,0xff,0xff,0xff,0xff,0xff,0xff
		,0xff,0xff,0xff,0xff,0xff,0xff,0xff,0xff,0xff,0xff,0xff,0xff,0xff,0xff,0xff,0xff,0xff,0xff,0xff,0xff,0xfb,0xd2,0xb2,0x8d,0x24,0x49,0xad,0xb1,0xb2,0xb2,0xb2,0xb2,0xd2,0xd2,0xd2,0xd2,0xb2,0xb2,0xb2,0xb2,0xb2,0xd2,0xd6,0xd6,0xd6,0xd6,0xd2,0xd2,0xb2,0xd2,0xb2,0x8d,0x69,0x49,0x45,0x45,0x69,0x8d,0xad,0xb2,0xb2,0xd2,0xb2,0xb1,0xad,0x69,0x24,0x44,0x45,0xd2,0xb2,0xad,0xd2,0xd7,0xff,0xff,0xff,0xff,0xff,0xff,0xff,0xff,0xff,0xff,0xff,0xff,0xff,0xff,0xff,0xff
		,0xff,0xff,0xff,0xff,0xff,0xff,0xff,0xff,0xff,0xff,0xff,0xff,0xff,0xff,0xff,0xff,0xff,0xff,0xff,0xff,0xd2,0x89,0xad,0xad,0x44,0x69,0xad,0xb1,0xb2,0xb2,0xad,0x89,0x45,0x45,0x25,0x24,0x25,0x49,0xae,0xd2,0xd2,0xd2,0xd6,0xd6,0xf7,0xd6,0xd2,0xd2,0xd2,0xd2,0xae,0x8e,0x49,0x00,0x00,0x69,0x69,0x44,0x89,0xad,0xb2,0xd2,0xd2,0xb2,0xad,0x8d,0x44,0x69,0xd2,0xd2,0xd2,0xd2,0xad,0xd2,0xfb,0xff,0xff,0xff,0xff,0xff,0xff,0xff,0xff,0xff,0xff,0xff,0xff,0xff,0xff,0xff
		,0xff,0xff,0xff,0xff,0xff,0xff,0xff,0xff,0xff,0xff,0xff,0xff,0xff,0xff,0xff,0xff,0xff,0xff,0xff,0xff,0xd2,0x89,0xad,0xb2,0x69,0x69,0xad,0xb2,0xd2,0xb2,0x8d,0x65,0x65,0xb2,0x69,0x00,0x20,0x8e,0x69,0xd2,0xd2,0xd2,0xd6,0xf6,0xf6,0xd6,0xd2,0xd2,0xd6,0xd6,0xae,0xae,0x8e,0x49,0x69,0xae,0x8d,0xad,0xae,0xb2,0xd2,0xd2,0xd2,0xb2,0xad,0xad,0x65,0xb2,0xd2,0xd2,0xd2,0xd2,0xd2,0xad,0xd7,0xff,0xff,0xff,0xff,0xff,0xff,0xff,0xff,0xff,0xff,0xff,0xff,0xff,0xff,0xff
		,0xff,0xff,0xff,0xff,0xff,0xff,0xff,0xff,0xff,0xff,0xff,0xff,0xff,0xff,0xff,0xff,0xff,0xff,0xff,0xff,0xd2,0xad,0xb2,0xb2,0x89,0x89,0xad,0xd2,0xd2,0xd2,0xd2,0xb2,0xb2,0xb2,0xb2,0x8e,0xae,0xb2,0xb2,0xd6,0xd6,0xd6,0xd6,0xf6,0xf6,0xd6,0xd2,0xd2,0xd6,0xd6,0xd6,0xd6,0xd2,0xd2,0xd2,0xd2,0xd2,0xd2,0xd6,0xd6,0xd6,0xd6,0xd2,0xb2,0xad,0xad,0x69,0xad,0xb2,0xd2,0xd6,0xd6,0xd2,0xad,0xd6,0xff,0xff,0xff,0xff,0xff,0xff,0xff,0xff,0xff,0xff,0xff,0xff,0xff,0xff,0xff
		,0xff,0xff,0xff,0xff,0xff,0xff,0xff,0xff,0xff,0xff,0xff,0xff,0xff,0xff,0xff,0xff,0xff,0xff,0xff,0xff,0xd2,0xae,0xd2,0xd2,0x89,0x8d,0xad,0xd2,0xd2,0xd6,0xd6,0xd6,0xd6,0xd6,0xd6,0xd2,0xd2,0xd6,0xd6,0xd6,0xd6,0xd6,0xd6,0xf6,0xf6,0xd6,0xd2,0xd2,0xd6,0xd6,0xd7,0xd6,0xd6,0xd6,0xd6,0xd6,0xd6,0xd6,0xd6,0xd6,0xd6,0xd6,0xd2,0xd2,0xb1,0xad,0x89,0xad,0xd6,0xd6,0xd6,0xd6,0xd2,0xae,0xd6,0xff,0xff,0xff,0xff,0xff,0xff,0xff,0xff,0xff,0xff,0xff,0xff,0xff,0xff,0xff
		,0xff,0xff,0xff,0xff,0xff,0xff,0xff,0xff,0xff,0xff,0xff,0xff,0xff,0xff,0xff,0xff,0xff,0xff,0xff,0xff,0xd2,0xd2,0xd2,0xd2,0x8d,0xad,0xb1,0xd2,0xd2,0xd6,0xd6,0xd6,0xd6,0xd6,0xd6,0xd6,0xd6,0xd6,0xd6,0xd6,0xd6,0xd6,0xd6,0xf6,0xfb,0xd6,0xd6,0xd2,0xd6,0xd6,0xd6,0xd6,0xd6,0xd6,0xd7,0xd7,0xd6,0xd6,0xd6,0xd6,0xd6,0xd6,0xd2,0xd2,0xb2,0xad,0x8d,0x8d,0xae,0xd2,0xd2,0xd6,0xd2,0xd2,0xfb,0xff,0xff,0xff,0xff,0xff,0xff,0xff,0xff,0xff,0xff,0xff,0xff,0xff,0xff,0xff
		,0xff,0xff,0xff,0xff,0xff,0xff,0xff,0xff,0xff,0xff,0xff,0xff,0xff,0xff,0xff,0xff,0xff,0xff,0xff,0xff,0xd6,0xd2,0xd2,0xad,0x89,0xad,0xb2,0xd2,0xd6,0xd6,0xd6,0xd6,0xd7,0xd7,0xd6,0xd6,0xd6,0xd6,0xd6,0xd6,0xd6,0xd6,0xd6,0xf6,0xfb,0xf6,0xd2,0xd2,0xd2,0xd6,0xd6,0xd7,0xd7,0xd7,0xd7,0xd7,0xd7,0xd6,0xd6,0xd6,0xd6,0xd6,0xd2,0xd2,0xb2,0xad,0x8d,0xae,0xae,0xd2,0xd2,0xd6,0xd2,0xd2,0xff,0xff,0xff,0xff,0xff,0xff,0xff,0xff,0xff,0xff,0xff,0xff,0xff,0xff,0xff,0xff
		,0xff,0xff,0xff,0xff,0xff,0xff,0xff,0xff,0xff,0xff,0xff,0xff,0xff,0xff,0xff,0xff,0xff,0xff,0xff,0xff,0xd6,0xd2,0xb2,0xad,0x89,0xad,0xb2,0xd2,0xd2,0xd6,0xd6,0xd7,0xdb,0xd7,0xd7,0xd6,0xf7,0xf7,0xf6,0xd6,0xd6,0xd6,0xd6,0xf6,0xfb,0xd6,0xd6,0xd2,0xd2,0xd6,0xd6,0xd7,0xfb,0xd7,0xfb,0xdb,0xd7,0xd6,0xd6,0xd6,0xd6,0xd6,0xd2,0xd2,0xb2,0xad,0x8d,0xd2,0xd2,0xd2,0xd2,0xd2,0xb2,0xd6,0xff,0xff,0xff,0xff,0xff,0xff,0xff,0xff,0xff,0xff,0xff,0xff,0xff,0xff,0xff,0xff
		,0xff,0xff,0xff,0xff,0xff,0xff,0xff,0xff,0xff,0xff,0xff,0xff,0xff,0xff,0xff,0xff,0xff,0xff,0xff,0xff,0xd7,0xd2,0xae,0x89,0x89,0xad,0xb2,0xd2,0xd6,0xd6,0xd6,0xd7,0xfb,0xfb,0xf7,0xf7,0xf7,0xf7,0xd6,0xd6,0xd6,0xd6,0xd6,0xf7,0xfb,0xd6,0xd6,0xd2,0xd2,0xd6,0xd6,0xf7,0xfb,0xfb,0xfb,0xfb,0xd7,0xd6,0xd6,0xd6,0xd6,0xd2,0xd2,0xd2,0xb2,0xad,0x8d,0xd2,0xd2,0xd2,0xd2,0xd2,0xb2,0xfb,0xff,0xff,0xff,0xff,0xff,0xff,0xff,0xff,0xff,0xff,0xff,0xff,0xff,0xff,0xff,0xff
		,0xff,0xff,0xff,0xff,0xff,0xff,0xff,0xff,0xff,0xff,0xff,0xff,0xff,0xff,0xff,0xff,0xff,0xff,0xff,0xff,0xfb,0xd2,0xb2,0x89,0x89,0xad,0xb1,0xd2,0xd6,0xd6,0xd6,0xd6,0xd7,0xfb,0xfb,0xfb,0xfb,0xf7,0xd6,0xd6,0xd2,0xd6,0xd6,0xfb,0xfb,0xd6,0xd6,0xd2,0xd2,0xd6,0xd6,0xd7,0xfb,0xfb,0xfb,0xfb,0xd7,0xd6,0xd6,0xd6,0xd6,0xd2,0xd2,0xd2,0xb1,0xad,0xad,0xd2,0xd2,0xd2,0xd6,0xd2,0xd2,0xff,0xff,0xff,0xff,0xff,0xff,0xff,0xff,0xff,0xff,0xff,0xff,0xff,0xff,0xff,0xff,0xff
		,0xff,0xff,0xff,0xff,0xff,0xff,0xff,0xff,0xff,0xff,0xff,0xff,0xff,0xff,0xff,0xff,0xff,0xff,0xff,0xff,0xff,0xd2,0xd2,0xa9,0xad,0xad,0xb2,0xd2,0xd6,0xd6,0xd6,0xd6,0xfb,0xfb,0xfb,0xfb,0xfb,0xf7,0xd6,0xd6,0xd6,0xd6,0xd6,0xfb,0xfb,0xd7,0xd6,0xd6,0xd2,0xd2,0xd6,0xd7,0xfb,0xfb,0xfb,0xfb,0xd7,0xd6,0xd6,0xd6,0xd6,0xd6,0xd2,0xb2,0xad,0x8d,0xad,0xd2,0xd2,0xd2,0xd6,0xd2,0xdb,0xff,0xff,0xff,0xff,0xff,0xff,0xff,0xff,0xff,0xff,0xff,0xff,0xff,0xff,0xff,0xff,0xff
		,0xff,0xff,0xff,0xff,0xff,0xff,0xff,0xff,0xff,0xff,0xff,0xff,0xff,0xff,0xff,0xff,0xff,0xff,0xff,0xff,0xff,0xd2,0xd2,0xad,0xad,0xad,0xad,0xd2,0xd6,0xd6,0xd6,0xd6,0xd7,0xfb,0xfb,0xfb,0xf7,0xf7,0xd6,0xd6,0xd6,0xd6,0xd2,0xd6,0xd6,0xd6,0xd2,0xd6,0xd6,0xd2,0xd6,0xd6,0xf7,0xfb,0xfb,0xd7,0xd7,0xd6,0xd6,0xd6,0xd6,0xd2,0xd2,0xb2,0xad,0x8d,0xad,0xd6,0xd2,0xd6,0xd6,0xd6,0xff,0xff,0xff,0xff,0xff,0xff,0xff,0xff,0xff,0xff,0xff,0xff,0xff,0xff,0xff,0xff,0xff,0xff
		,0xff,0xff,0xff,0xff,0xff,0xff,0xff,0xff,0xff,0xff,0xff,0xff,0xff,0xff,0xff,0xff,0xff,0xff,0xff,0xff,0xff,0xd7,0xd2,0xd2,0xb2,0xad,0xad,0xb2,0xd2,0xd6,0xd6,0xd6,0xd7,0xfb,0xfb,0xfb,0xf7,0xf7,0xd6,0xd2,0xd6,0xd2,0xb2,0xd2,0xd2,0xb2,0xad,0xb2,0xd2,0xd2,0xd6,0xd6,0xd6,0xd7,0xd7,0xd7,0xd6,0xd6,0xd6,0xd6,0xd6,0xd2,0xb2,0xb2,0xad,0x8d,0xb2,0xd6,0xd6,0xd6,0xd6,0xfb,0xff,0xff,0xff,0xff,0xff,0xff,0xff,0xff,0xff,0xff,0xff,0xff,0xff,0xff,0xff,0xff,0xff,0xff
		,0xff,0xff,0xff,0xff,0xff,0xff,0xff,0xff,0xff,0xff,0xff,0xff,0xff,0xff,0xff,0xff,0xff,0xff,0xff,0xff,0xff,0xff,0xd2,0xd2,0xd2,0xad,0xad,0xb2,0xd2,0xd6,0xd6,0xd6,0xd7,0xd7,0xd7,0xf7,0xf7,0xd7,0xd6,0xd2,0xb2,0x65,0x44,0x8d,0x8d,0x8d,0x65,0x44,0xad,0xb2,0xd6,0xd6,0xd6,0xd7,0xd7,0xd7,0xd6,0xd6,0xd6,0xd6,0xd6,0xd2,0xb2,0xb2,0xad,0x8d,0xd2,0xd6,0xd6,0xd6,0xd6,0xff,0xff,0xff,0xff,0xff,0xff,0xff,0xff,0xff,0xff,0xff,0xff,0xff,0xff,0xff,0xff,0xff,0xff,0xff
		,0xff,0xff,0xff,0xff,0xff,0xff,0xff,0xff,0xff,0xff,0xff,0xff,0xff,0xff,0xff,0xff,0xff,0xff,0xff,0xff,0xff,0xff,0xd6,0xd2,0xd2,0xad,0xad,0xad,0xd2,0xd2,0xd6,0xd6,0xd6,0xd6,0xd6,0xd7,0xf6,0xd6,0xd6,0xd2,0xad,0xb2,0xb2,0xb2,0xad,0xb2,0xb2,0xb2,0xad,0xb2,0xd6,0xd6,0xd6,0xd6,0xd7,0xd6,0xd6,0xd6,0xd6,0xd6,0xd2,0xd2,0xb2,0xad,0xad,0x8d,0xd6,0xd6,0xd6,0xd6,0xff,0xff,0xff,0xff,0xff,0xff,0xff,0xff,0xff,0xff,0xff,0xff,0xff,0xff,0xff,0xff,0xff,0xff,0xff,0xff
		,0xff,0xff,0xff,0xff,0xff,0xff,0xff,0xff,0xff,0xff,0xff,0xff,0xff,0xff,0xff,0xff,0xff,0xff,0xff,0xff,0xff,0xff,0xfb,0xd2,0xd2,0xd2,0x8d,0xad,0xb2,0xd2,0xd6,0xd6,0xd6,0xd6,0xd6,0xd6,0xd6,0xf6,0xd6,0xd6,0xd2,0xd2,0xd2,0xd6,0xd2,0xd2,0xd2,0xd2,0xd2,0xd6,0xd6,0xd6,0xd6,0xd6,0xd6,0xd6,0xd6,0xd6,0xd6,0xd2,0xd2,0xb2,0xb2,0xad,0x8d,0xad,0xd6,0xd6,0xd6,0xfb,0xff,0xff,0xff,0xff,0xff,0xff,0xff,0xff,0xff,0xff,0xff,0xff,0xff,0xff,0xff,0xff,0xff,0xff,0xff,0xff
		,0xff,0xff,0xff,0xff,0xff,0xff,0xff,0xff,0xff,0xff,0xff,0xff,0xff,0xff,0xff,0xff,0xff,0xff,0xff,0xff,0xff,0xff,0xff,0xd6,0xb2,0xd2,0x8d,0xad,0xb2,0xd2,0xd2,0xd6,0xd6,0xd6,0xd6,0xd6,0xd6,0xd6,0xd6,0xd6,0xd6,0xd6,0xd6,0xd6,0xd6,0xd6,0xd6,0xd6,0xd6,0xd6,0xd6,0xd6,0xd6,0xd6,0xd6,0xd6,0xd6,0xd6,0xd6,0xd2,0xd2,0xb2,0xb2,0xad,0x8d,0xb2,0xd6,0xfb,0xff,0xff,0xff,0xff,0xff,0xff,0xff,0xff,0xff,0xff,0xff,0xff,0xff,0xff,0xff,0xff,0xff,0xff,0xff,0xff,0xff,0xff
		,0xff,0xff,0xff,0xff,0xff,0xff,0xff,0xff,0xff,0xff,0xff,0xff,0xff,0xff,0xff,0xff,0xff,0xff,0xff,0xff,0xff,0xff,0xff,0xff,0xff,0xdb,0xb2,0x8d,0xae,0xb2,0xd2,0xd2,0xd6,0xd6,0xd6,0xd6,0xd6,0xd6,0xd6,0xd6,0xd6,0xd6,0xd6,0xd6,0xd6,0xd6,0xd6,0xd6,0xd6,0xd6,0xd6,0xd6,0xd6,0xd6,0xd6,0xd6,0xd6,0xd2,0xd2,0xd2,0xb2,0xb2,0xad,0xad,0x8d,0xff,0xff,0xff,0xff,0xff,0xff,0xff,0xff,0xff,0xff,0xff,0xff,0xff,0xff,0xff,0xff,0xff,0xff,0xff,0xff,0xff,0xff,0xff,0xff,0xff
		,0xff,0xff,0xff,0xff,0xff,0xff,0xff,0xff,0xff,0xff,0xff,0xff,0xff,0xff,0xff,0xff,0xff,0xff,0xff,0xff,0xff,0xff,0xff,0xff,0xff,0xff,0xff,0xad,0xae,0xb2,0xb2,0xd2,0xd2,0xd6,0xd6,0xd6,0xd6,0xd6,0xd6,0xd6,0xd6,0xd6,0xd2,0xd2,0xd6,0xd2,0xd2,0xd6,0xd6,0xd2,0xd2,0xd6,0xd2,0xd2,0xd6,0xd6,0xd6,0xd2,0xd2,0xd2,0xb2,0xb2,0xad,0x8d,0xd6,0xff,0xff,0xff,0xff,0xff,0xff,0xff,0xff,0xff,0xff,0xff,0xff,0xff,0xff,0xff,0xff,0xff,0xff,0xff,0xff,0xff,0xff,0xff,0xff,0xff
		,0xff,0xff,0xff,0xff,0xff,0xff,0xff,0xff,0xff,0xff,0xff,0xff,0xff,0xff,0xff,0xff,0xff,0xff,0xff,0xff,0xff,0xff,0xff,0xff,0xff,0xff,0xff,0xb6,0xad,0xb2,0xb2,0xd2,0xd2,0xd2,0xd2,0xd6,0xd2,0xd2,0xd2,0xd2,0xd2,0xae,0xce,0xae,0xce,0xae,0xae,0xae,0xd2,0xd2,0xb2,0xb2,0xd2,0xd2,0xd2,0xd2,0xd2,0xd2,0xd2,0xb2,0xb2,0xb2,0xad,0x8d,0xff,0xff,0xff,0xff,0xff,0xff,0xff,0xff,0xff,0xff,0xff,0xff,0xff,0xff,0xff,0xff,0xff,0xff,0xff,0xff,0xff,0xff,0xff,0xff,0xff,0xff
		,0xff,0xff,0xff,0xff,0xff,0xff,0xff,0xff,0xff,0xff,0xff,0xff,0xff,0xff,0xff,0xff,0xff,0xff,0xff,0xff,0xff,0xff,0xff,0xff,0xff,0xff,0xff,0xfb,0xad,0xb2,0xb2,0xd2,0xd2,0xd2,0xd2,0xd2,0xb2,0xb2,0xae,0xad,0xa9,0xa9,0xae,0xad,0xa9,0xaa,0xa9,0xa9,0x89,0xad,0xad,0xad,0xb2,0xb2,0xd2,0xd2,0xd2,0xd2,0xb2,0xb2,0xb2,0xae,0x8d,0xb2,0xff,0xff,0xff,0xff,0xff,0xff,0xff,0xff,0xff,0xff,0xff,0xff,0xff,0xff,0xff,0xff,0xff,0xff,0xff,0xff,0xff,0xff,0xff,0xff,0xff,0xff
		,0xff,0xff,0xff,0xff,0xff,0xff,0xff,0xff,0xff,0xff,0xff,0xff,0xff,0xff,0xff,0xff,0xff,0xff,0xff,0xff,0xff,0xff,0xff,0xff,0xff,0xff,0xff,0xff,0xb2,0xae,0xb2,0xb2,0xd2,0xd2,0xd6,0xd2,0xb2,0xad,0x89,0x89,0x89,0x89,0x89,0xa9,0xa5,0x85,0x85,0x89,0x89,0x85,0x89,0x89,0xad,0xb2,0xb2,0xd2,0xd2,0xd2,0xb2,0xb2,0xb2,0xad,0x8d,0xd6,0xff,0xff,0xff,0xff,0xff,0xff,0xff,0xff,0xff,0xff,0xff,0xff,0xff,0xff,0xff,0xff,0xff,0xff,0xff,0xff,0xff,0xff,0xff,0xff,0xff,0xff
		,0xff,0xff,0xff,0xff,0xff,0xff,0xff,0xff,0xff,0xff,0xff,0xff,0xff,0xff,0xff,0xff,0xff,0xff,0xff,0xff,0xff,0xff,0xff,0xff,0xff,0xff,0xff,0xff,0xdb,0xad,0xb2,0xb2,0xb2,0xd2,0xd6,0xd2,0xb2,0xad,0xae,0x89,0x89,0xaa,0xce,0xca,0xca,0xca,0xce,0xa9,0xa9,0x89,0x89,0xae,0xad,0xb2,0xb2,0xb2,0xd2,0xb2,0xb2,0xb2,0xb2,0xad,0x8d,0xff,0xff,0xff,0xff,0xff,0xff,0xff,0xff,0xff,0xff,0xff,0xff,0xff,0xff,0xff,0xff,0xff,0xff,0xff,0xff,0xff,0xff,0xff,0xff,0xff,0xff,0xff
		,0xff,0xff,0xff,0xff,0xff,0xff,0xff,0xff,0xff,0xff,0xff,0xff,0xff,0xff,0xff,0xff,0xff,0xff,0xff,0xff,0xff,0xff,0xff,0xff,0xff,0xff,0xff,0xff,0xff,0xb2,0xb2,0xb2,0xb2,0xb2,0xd2,0xd2,0xb2,0xad,0xae,0xae,0xae,0xce,0xd2,0xf2,0xf2,0xf2,0xf3,0xce,0xce,0xae,0xae,0xae,0xae,0xb2,0xb2,0xb2,0xb2,0xb2,0xb2,0xb2,0xb2,0x8d,0xb2,0xff,0xff,0xff,0xff,0xff,0xff,0xff,0xff,0xff,0xff,0xff,0xff,0xff,0xff,0xff,0xff,0xff,0xff,0xff,0xff,0xff,0xff,0xff,0xff,0xff,0xff,0xff
		,0xff,0xff,0xff,0xff,0xff,0xff,0xff,0xff,0xff,0xff,0xff,0xff,0xff,0xff,0xff,0xff,0xff,0xff,0xff,0xff,0xff,0xff,0xff,0xff,0xff,0xff,0xff,0xff,0xff,0xd7,0xae,0xb2,0xb2,0xb2,0xb2,0xb2,0xd2,0xd2,0xb2,0xae,0xa9,0xaa,0xce,0xce,0xd2,0xd2,0xce,0xa9,0xad,0xad,0xad,0xb2,0xb2,0xb2,0xb2,0xb2,0xb2,0xb2,0xb2,0xb2,0xae,0x8d,0xdb,0xff,0xff,0xff,0xff,0xff,0xff,0xff,0xff,0xff,0xff,0xff,0xff,0xff,0xff,0xff,0xff,0xff,0xff,0xff,0xff,0xff,0xff,0xff,0xff,0xff,0xff,0xff
		,0xff,0xff,0xff,0xff,0xff,0xff,0xff,0xff,0xff,0xff,0xff,0xff,0xff,0xff,0xff,0xff,0xff,0xff,0xff,0xff,0xff,0xff,0xff,0xff,0xff,0xff,0xff,0xff,0xff,0xff,0xb2,0xb2,0xb2,0xb2,0xb2,0xb2,0xd2,0xd2,0xd2,0xb2,0xad,0xa9,0xa9,0xa9,0xa9,0xa9,0xa9,0xa9,0xad,0xad,0xae,0xb2,0xb2,0xb2,0xb2,0xb2,0xb2,0xb2,0xb2,0xb2,0xad,0x8d,0xff,0xff,0xff,0xff,0xff,0xff,0xff,0xff,0xff,0xff,0xff,0xff,0xff,0xff,0xff,0xff,0xff,0xff,0xff,0xff,0xff,0xff,0xff,0xff,0xff,0xff,0xff,0xff
		,0xff,0xff,0xff,0xff,0xff,0xff,0xff,0xff,0xff,0xff,0xff,0xff,0xff,0xff,0xff,0xff,0xff,0xff,0xff,0xff,0xff,0xff,0xff,0xff,0xff,0xff,0xff,0xff,0xff,0xff,0xdb,0xae,0xb2,0xb2,0xb2,0xb2,0xd2,0xd2,0xd2,0xd2,0xb2,0xad,0x89,0x89,0x89,0x89,0x89,0x89,0xad,0xae,0xb2,0xb2,0xb2,0xb2,0xb2,0xb2,0xb2,0xb2,0xb2,0xae,0x8d,0x8d,0xff,0xff,0xff,0xff,0xff,0xff,0xff,0xff,0xff,0xff,0xff,0xff,0xff,0xff,0xff,0xff,0xff,0xff,0xff,0xff,0xff,0xff,0xff,0xff,0xff,0xff,0xff,0xff
		,0xff,0xff,0xff,0xff,0xff,0xff,0xff,0xff,0xff,0xff,0xff,0xff,0xff,0xff,0xff,0xff,0xff,0xff,0xff,0xff,0xff,0xff,0xff,0xff,0xff,0xff,0xff,0xff,0xff,0xff,0xff,0xb2,0xb2,0xb2,0xb2,0xb2,0xd2,0xd2,0xd2,0xd2,0xd2,0xb2,0xb2,0xb2,0xb2,0xb2,0xae,0xae,0xb2,0xb2,0xb2,0xb2,0xb2,0xb2,0xb2,0xb2,0xb2,0xb2,0xb2,0xae,0x8d,0x8d,0xff,0xff,0xff,0xff,0xff,0xff,0xff,0xff,0xff,0xff,0xff,0xff,0xff,0xff,0xff,0xff,0xff,0xff,0xff,0xff,0xff,0xff,0xff,0xff,0xff,0xff,0xff,0xff
		,0xff,0xff,0xff,0xff,0xff,0xff,0xff,0xff,0xff,0xff,0xff,0xff,0xff,0xff,0xff,0xff,0xff,0xff,0xff,0xff,0xff,0xff,0xff,0xff,0xff,0xff,0xff,0xff,0xff,0xff,0xff,0xd6,0xae,0xb2,0xb2,0xb2,0xd2,0xd2,0xd2,0xd2,0xd2,0xd2,0xd2,0xd2,0xd2,0xd2,0xd2,0xd2,0xd2,0xd2,0xd2,0xd2,0xd2,0xd2,0xb2,0xb2,0xb2,0xb2,0xb2,0x8d,0x8d,0x8d,0xff,0xff,0xff,0xff,0xff,0xff,0xff,0xff,0xff,0xff,0xff,0xff,0xff,0xff,0xff,0xff,0xff,0xff,0xff,0xff,0xff,0xff,0xff,0xff,0xff,0xff,0xff,0xff
		,0xff,0xff,0xff,0xff,0xff,0xff,0xff,0xff,0xff,0xff,0xff,0xff,0xff,0xff,0xff,0xff,0xff,0xff,0xff,0xff,0xff,0xff,0xff,0xff,0xff,0xff,0xff,0xff,0xff,0xff,0xff,0xd7,0xad,0xb2,0xb2,0xb2,0xb2,0xd2,0xd2,0xd2,0xd2,0xd2,0xd6,0xd6,0xd6,0xd6,0xd6,0xd6,0xd6,0xd2,0xd2,0xd2,0xd2,0xd2,0xb2,0xb2,0xb2,0xae,0xae,0x8d,0x8d,0x8d,0xb7,0xff,0xff,0xff,0xff,0xff,0xff,0xff,0xff,0xff,0xff,0xff,0xff,0xff,0xff,0xff,0xff,0xff,0xff,0xff,0xff,0xff,0xff,0xff,0xff,0xff,0xff,0xff
		,0xff,0xff,0xff,0xff,0xff,0xff,0xff,0xff,0xff,0xff,0xff,0xff,0xff,0xff,0xff,0xff,0xff,0xff,0xff,0xff,0xff,0xff,0xff,0xff,0xff,0xff,0xff,0xff,0xff,0xff,0xff,0xb6,0xad,0xb2,0xb2,0xb2,0xb2,0xb2,0xd2,0xd2,0xd2,0xd2,0xd2,0xd2,0xd2,0xd2,0xd6,0xd6,0xd2,0xd2,0xd2,0xb2,0xd2,0xb2,0xb2,0xb2,0xb2,0xae,0x8e,0xad,0xad,0xad,0xb7,0xbb,0xff,0xff,0xff,0xff,0xff,0xff,0xff,0xff,0xff,0xff,0xff,0xff,0xff,0xff,0xff,0xff,0xff,0xff,0xff,0xff,0xff,0xff,0xff,0xff,0xff,0xff
		,0xff,0xff,0xff,0xff,0xff,0xff,0xff,0xff,0xff,0xff,0xff,0xff,0xff,0xff,0xff,0xff,0xff,0xff,0xff,0xff,0xff,0xff,0xff,0xff,0xff,0xff,0xff,0xff,0xff,0xff,0xdf,0xb6,0xb2,0xae,0xb2,0xb2,0xb2,0xb2,0xb2,0xd2,0xd2,0xd2,0xd2,0xd2,0xd2,0xd2,0xd2,0xd2,0xd2,0xd2,0xd2,0xb2,0xb2,0xb2,0xb2,0xb2,0xae,0xae,0xae,0xae,0xad,0xad,0xb6,0x97,0xff,0xff,0xff,0xff,0xff,0xff,0xff,0xff,0xff,0xff,0xff,0xff,0xff,0xff,0xff,0xff,0xff,0xff,0xff,0xff,0xff,0xff,0xff,0xff,0xff,0xff
		,0xff,0xff,0xff,0xff,0xff,0xff,0xff,0xff,0xff,0xff,0xff,0xff,0xff,0xff,0xff,0xff,0xff,0xff,0xff,0xff,0xff,0xff,0xff,0xff,0xff,0xff,0xff,0xff,0xff,0xff,0xbb,0xb6,0xae,0xb2,0xae,0xb2,0xb2,0xb2,0xb2,0xb2,0xb2,0xd2,0xd2,0xb2,0xb2,0xb2,0xb2,0xb2,0xb2,0xb2,0xb2,0xb2,0xb2,0xb2,0xb2,0xb2,0x8e,0x8e,0xb2,0xb2,0xad,0xad,0xb6,0xb7,0xdb,0xff,0xff,0xff,0xff,0xff,0xff,0xff,0xff,0xff,0xff,0xff,0xff,0xff,0xff,0xff,0xff,0xff,0xff,0xff,0xff,0xff,0xff,0xff,0xff,0xff
		,0xff,0xff,0xff,0xff,0xff,0xff,0xff,0xff,0xff,0xff,0xff,0xff,0xff,0xff,0xff,0xff,0xff,0xff,0xff,0xff,0xff,0xff,0xff,0xff,0xff,0xff,0xff,0xff,0xff,0xff,0xbb,0xb7,0xb2,0xb2,0xb2,0xb2,0xb2,0xb2,0xae,0xb2,0xb2,0xb2,0xb2,0xb2,0xb2,0xae,0xae,0xb2,0xb2,0xb2,0xb2,0xb2,0xb2,0xb2,0xb2,0x8e,0x8e,0xb2,0xb2,0xb2,0xad,0xb2,0xbb,0xbb,0xbb,0xff,0xff,0xff,0xff,0xff,0xff,0xff,0xff,0xff,0xff,0xff,0xff,0xff,0xff,0xff,0xff,0xff,0xff,0xff,0xff,0xff,0xff,0xff,0xff,0xff
		,0xff,0xff,0xff,0xff,0xff,0xff,0xff,0xff,0xff,0xff,0xff,0xff,0xff,0xff,0xff,0xff,0xff,0xff,0xff,0xff,0xff,0xff,0xff,0xff,0xff,0xff,0xff,0xff,0xff,0xbb,0xbb,0xbb,0xb2,0xb2,0xb2,0xb2,0xae,0xb2,0xae,0xae,0xae,0xb2,0xb2,0xb2,0xae,0xae,0xae,0xae,0xae,0xae,0xae,0xae,0xae,0x8e,0x8e,0x8e,0xb2,0xb2,0xb2,0xb2,0xad,0xb6,0xbb,0xbb,0xbb,0xbb,0xff,0xff,0xff,0xff,0xff,0xff,0xff,0xff,0xff,0xff,0xff,0xff,0xff,0xff,0xff,0xff,0xff,0xff,0xff,0xff,0xff,0xff,0xff,0xff
		,0xff,0xff,0xff,0xff,0xff,0xff,0xff,0xff,0xff,0xff,0xff,0xff,0xff,0xff,0xff,0xff,0xff,0xff,0xff,0xff,0xff,0xff,0xff,0xff,0xff,0xff,0xff,0xff,0xdf,0xbb,0xbb,0xbb,0xbb,0xb2,0xb2,0xb2,0xb2,0xae,0x8e,0x8e,0x8e,0x8e,0x8e,0x8d,0x8d,0x8d,0x8d,0x8d,0x8d,0x8e,0x8e,0x8e,0x8e,0x8e,0x8e,0xb2,0xb2,0xb2,0xb2,0xb2,0xb2,0xbb,0xbb,0xbb,0xbb,0xbb,0xdb,0xff,0xff,0xff,0xff,0xff,0xff,0xff,0xff,0xff,0xff,0xff,0xff,0xff,0xff,0xff,0xff,0xff,0xff,0xff,0xff,0xff,0xff,0xff
		,0xff,0xff,0xff,0xff,0xff,0xff,0xff,0xff,0xff,0xff,0xff,0xff,0xff,0xff,0xff,0xff,0xff,0xff,0xff,0xff,0xff,0xff,0xff,0xff,0xff,0xff,0xff,0xff,0xbb,0xbb,0xbb,0xbb,0xdb,0xdb,0xb2,0xb2,0xb2,0xb2,0xae,0x8e,0x8e,0x8e,0x8d,0x8d,0x8d,0x89,0x8d,0x8d,0x8d,0x8d,0x8d,0x8d,0x8d,0x8e,0xb2,0xb2,0xb2,0xb2,0xb2,0xb2,0xbb,0xbb,0xbb,0xbb,0xbb,0xbb,0xbb,0xdb,0xff,0xff,0xff,0xff,0xff,0xff,0xff,0xff,0xff,0xff,0xff,0xff,0xff,0xff,0xff,0xff,0xff,0xff,0xff,0xff,0xff,0xff
		,0xff,0xff,0xff,0xff,0xff,0xff,0xff,0xff,0xff,0xff,0xff,0xff,0xff,0xff,0xff,0xff,0xff,0xff,0xff,0xff,0xff,0xff,0xff,0xff,0xff,0xdf,0xbb,0xbb,0xbb,0xbb,0xbb,0xbb,0xdb,0xdb,0xdb,0xb2,0xb2,0xb2,0xb2,0xae,0x8e,0x8e,0x8d,0x8d,0x8d,0x8d,0x8d,0x8d,0x8d,0x8d,0x8d,0x8d,0xae,0xb2,0xb2,0xb2,0xb2,0xb2,0xb2,0xbb,0xbb,0xbb,0xbb,0xbb,0xbb,0xbb,0xbb,0xbb,0xbb,0xbb,0xff,0xff,0xff,0xff,0xff,0xff,0xff,0xff,0xff,0xff,0xff,0xff,0xff,0xff,0xff,0xff,0xff,0xff,0xff,0xff
		,0xff,0xff,0xff,0xff,0xff,0xff,0xff,0xff,0xff,0xff,0xff,0xff,0xff,0xff,0xff,0xff,0xff,0xff,0xff,0xff,0xff,0xff,0xff,0xdb,0xbb,0xbb,0xbb,0xbb,0xbb,0xbb,0xbb,0xdb,0xdb,0xdb,0xdb,0xdb,0xb2,0xb2,0xae,0xae,0xae,0x8e,0x8d,0x8d,0x89,0x89,0x89,0x89,0x89,0x8d,0x8d,0xae,0xb2,0xb2,0xb2,0xb2,0xb2,0xb6,0xdb,0xdb,0xbb,0xbb,0xbb,0xbb,0xbb,0xbb,0xbb,0xbb,0xbb,0xbb,0xbb,0xbb,0xdf,0xff,0xff,0xff,0xff,0xff,0xff,0xff,0xff,0xff,0xff,0xff,0xff,0xff,0xff,0xff,0xff,0xff
		,0xff,0xff,0xff,0xff,0xff,0xff,0xff,0xff,0xff,0xff,0xff,0xff,0xff,0xff,0xff,0xff,0xff,0xff,0xff,0xff,0xdf,0xbb,0xbb,0xbb,0xbb,0xbb,0xbb,0xbb,0xbb,0xbb,0xbb,0xbb,0xbb,0xdb,0xdb,0xdb,0xdb,0xb6,0xae,0xae,0xae,0xae,0x8d,0x8d,0x8d,0x89,0x89,0x89,0x8d,0xae,0xb2,0xb2,0xb2,0xb2,0xb2,0xb2,0xb6,0xdb,0xdb,0xbb,0xdb,0xdb,0xbb,0xbb,0xbb,0xbb,0xbb,0xdb,0xbb,0xbb,0xbb,0xbb,0xbb,0xbb,0xdb,0xff,0xff,0xff,0xff,0xff,0xff,0xff,0xff,0xff,0xff,0xff,0xff,0xff,0xff,0xff
		,0xff,0xff,0xff,0xff,0xff,0xff,0xff,0xff,0xff,0xff,0xff,0xff,0xff,0xff,0xff,0xff,0xff,0xff,0xbb,0xbb,0xbb,0xbb,0xbb,0xbb,0xbb,0xbb,0xdb,0xbb,0xbb,0xbb,0xbb,0xbb,0xbb,0xdb,0xdb,0xdb,0xdb,0xdb,0xb7,0xb2,0xae,0xae,0xae,0xae,0xae,0xae,0xb2,0xb2,0xb2,0xb2,0xb2,0xb2,0xb2,0xb2,0xb6,0xdb,0xdb,0xdb,0xdb,0xdb,0xdb,0xbb,0xbb,0xbb,0xdb,0xbb,0xbb,0xdb,0xdb,0xdb,0xdb,0xdb,0xdb,0xbb,0xbb,0xbb,0xbb,0xdf,0xff,0xff,0xff,0xff,0xff,0xff,0xff,0xff,0xff,0xff,0xff,0xff
		,0xff,0xff,0xff,0xff,0xff,0xff,0xff,0xff,0xff,0xff,0xff,0xff,0xff,0xff,0xff,0xdf,0xbb,0xbb,0xbb,0xdb,0xdb,0xdb,0xdb,0xdb,0xdb,0xbb,0xdb,0xbb,0xbb,0xbb,0xbb,0xdb,0xbb,0xbb,0xdb,0xdb,0xdb,0xdb,0xdb,0xdb,0xb2,0xb2,0xb2,0xb2,0xb2,0xb2,0xb2,0xb2,0xb2,0xb2,0xb2,0xb2,0xb2,0xd7,0xdb,0xdb,0xdb,0xdb,0xdb,0xdb,0xdb,0xbb,0xbb,0xdb,0xdb,0xbb,0xdb,0xdb,0xdb,0xdb,0xdf,0xdf,0xdb,0xdf,0xdf,0xdf,0xdf,0xdf,0xdb,0xdf,0xff,0xff,0xff,0xff,0xff,0xff,0xff,0xff,0xff,0xff
		,0xff,0xff,0xff,0xff,0xff,0xff,0xff,0xff,0xff,0xff,0xff,0xff,0xff,0xdf,0xbb,0xbb,0xdb,0xdb,0xdb,0xdb,0xdb,0xdb,0xdb,0xdb,0xdb,0xdb,0xdb,0xdb,0xbb,0xbb,0xdb,0xdb,0xdb,0xbb,0xdb,0xdb,0xdb,0xdb,0xdb,0xdb,0xdb,0xb7,0xb2,0xb2,0xb2,0xb2,0xb2,0xb2,0xb2,0xb2,0xb2,0xb6,0xdb,0xdb,0xdb,0xdf,0xdb,0xdb,0xdb,0xdb,0xbb,0xbb,0xdb,0xdb,0xdb,0xbb,0xdf,0xdb,0xdf,0xdf,0xdf,0xdf,0xdf,0xdf,0xdf,0xdf,0xdf,0xdf,0xdf,0xdf,0xdf,0xdb,0xdf,0xff,0xff,0xff,0xff,0xff,0xff,0xff
		,0xff,0xff,0xff,0xff,0xff,0xff,0xff,0xff,0xff,0xff,0xdf,0xbb,0xbb,0xdb,0xdb,0xdb,0xdb,0xdf,0xdf,0xdf,0xdf,0xdf,0xdf,0xdb,0xdb,0xdb,0xdb,0xdf,0xdb,0xbb,0xdb,0xdb,0xdb,0xdb,0xbb,0xbb,0xbb,0xdb,0xdb,0xdb,0xdb,0xdb,0xb7,0xb2,0xb2,0xb2,0xae,0xae,0xb2,0xb2,0xbb,0xdb,0xdb,0xdb,0xdb,0xdb,0xdb,0xdb,0xbb,0xbb,0xbb,0xdb,0xdb,0xdb,0xdb,0xdb,0xdf,0xdb,0xdf,0xdf,0xdf,0xdf,0xdf,0xdf,0xdf,0xdf,0xdf,0xdf,0xdf,0xdf,0xdf,0xdf,0xdb,0xdb,0xdb,0xdf,0xff,0xff,0xff,0xff
		,0xff,0xff,0xff,0xff,0xff,0xff,0xff,0xdf,0xdb,0xdb,0xdb,0xdb,0xdf,0xdf,0xdf,0xdf,0xdf,0xdf,0xdf,0xdf,0xdf,0xdf,0xdf,0xdf,0xdf,0xdb,0xdb,0xdf,0xdf,0xdb,0xdb,0xdb,0xdb,0xdb,0xbb,0xbb,0xbb,0xdb,0xdb,0xdb,0xdb,0xdb,0xb7,0xbb,0xb7,0xb2,0xb2,0xb7,0xbb,0xbb,0xbb,0xdb,0xdf,0xdf,0xdb,0xdb,0xdb,0xdb,0xbb,0xbb,0xdb,0xdb,0xdb,0xdb,0xdb,0xdf,0xdf,0xdb,0xdf,0xdf,0xdf,0xdf,0xdf,0xdf,0xdf,0xdf,0xdf,0xdf,0xdf,0xdb,0xdb,0xdb,0xdb,0xdb,0xdb,0xdb,0xdb,0xdb,0xdf,0xdf
		,0xff,0xff,0xff,0xff,0xdf,0xdb,0xdb,0xdb,0xdf,0xdf,0xdf,0xdf,0xdf,0xdf,0xdf,0xdf,0xdf,0xdf,0xdf,0xdf,0xdf,0xdf,0xdf,0xdf,0xdf,0xdb,0xdb,0xdf,0xdf,0xdb,0xdb,0xdb,0xdb,0xdb,0xdb,0xdb,0xdb,0xdb,0xdb,0xdb,0xdb,0xbb,0xb7,0xbb,0xbb,0xbb,0xbb,0xbb,0xbb,0xbb,0xb7,0xdb,0xdb,0xdb,0xdb,0xdb,0xdb,0xbb,0xbb,0xdb,0xdb,0xdb,0xdb,0xdb,0xdf,0xdf,0xdf,0xdf,0xdf,0xdf,0xdf,0xdf,0xdf,0xdf,0xdf,0xdf,0xdf,0xdf,0xdf,0xdf,0xdf,0xdf,0xdb,0xdf,0xdf,0xdf,0xdb,0xdb,0xdb,0xdb
		,0xff,0xff,0xdf,0xdb,0xdf,0xdf,0xdf,0xdf,0xdf,0xdf,0xdf,0xdf,0xdf,0xdf,0xdf,0xdf,0xdf,0xdf,0xdf,0xdf,0xdf,0xdf,0xdf,0xdf,0xdf,0xdb,0xdb,0xdf,0xdf,0xdb,0xdb,0xdb,0xdb,0xdb,0xdb,0xdb,0xdb,0xdb,0xdb,0xdb,0xdb,0xb7,0x97,0xb7,0xdb,0xbb,0xdb,0xbb,0xbb,0xbb,0xb7,0xb7,0xdb,0xdb,0xdb,0xbb,0xdb,0xbb,0xdb,0xdb,0xdb,0xdb,0xdb,0xdf,0xdf,0xdf,0xdb,0xdf,0xdf,0xdf,0xdf,0xdf,0xdf,0xdf,0xdf,0xdf,0xdf,0xdf,0xdf,0xdf,0xdf,0xdf,0xdf,0xdf,0xdf,0xdf,0xdf,0xdf,0xdf,0xdf
		,0xdf,0xdf,0xdf,0xdf,0xdf,0xdf,0xdf,0xdf,0xdf,0xdf,0xdf,0xdf,0xdf,0xdf,0xdf,0xdf,0xdf,0xdf,0xdf,0xdf,0xdf,0xdf,0xdf,0xdf,0xdf,0xdf,0xdf,0xdf,0xdf,0xdf,0xdb,0xdb,0xdb,0xdb,0xdf,0xdb,0xdb,0xdb,0xdb,0xdb,0xdb,0x97,0xbb,0xdb,0xdb,0xdb,0xdb,0xdb,0xdb,0xdb,0xbb,0xb7,0xdb,0xdb,0xdb,0xdb,0xbb,0xbb,0xdb,0xdb,0xdf,0xdf,0xdf,0xdf,0xdf,0xdf,0xdb,0xdf,0xdf,0xdf,0xdf,0xdf,0xdf,0xdf,0xdf,0xdf,0xdf,0xdf,0xdf,0xdf,0xdf,0xdf,0xdf,0xdf,0xdf,0xdf,0xdf,0xdf,0xdf,0xdf
		,0xdf,0xdf,0xdf,0xdf,0xdf,0xdf,0xdf,0xdf,0xdf,0xdf,0xdf,0xdf,0xdf,0xdf,0xdf,0xdf,0xdf,0xdf,0xdf,0xdf,0xdf,0xdf,0xdf,0xdf,0xdf,0xdf,0xdf,0xdf,0xdf,0xdf,0xdf,0xdb,0xdf,0xdf,0xdf,0xdf,0xdf,0xdf,0xdf,0xdb,0xbb,0x97,0xbb,0xdb,0xdb,0xdb,0xdb,0xdb,0xdf,0xdb,0xbb,0xb7,0xdb,0xdb,0xdb,0xdb,0xdb,0xdf,0xdf,0xdf,0xdf,0xdf,0xdf,0xdf,0xdf,0xdf,0xdf,0xdf,0xdf,0xdf,0xdf,0xdf,0xdf,0xdf,0xdf,0xdf,0xdf,0xdf,0xdf,0xdf,0xdf,0xdf,0xdf,0xdf,0xdf,0xdf,0xdf,0xdf,0xdf,0xdf
		,0xdf,0xdf,0xdf,0xdf,0xdf,0xdf,0xdf,0xdf,0xdf,0xdf,0xdf,0xdf,0xdf,0xdf,0xdf,0xdf,0xdf,0xdf,0xdf,0xdf,0xdf,0xdf,0xdf,0xdf,0xdf,0xdf,0xdf,0xdf,0xdf,0xdf,0xdf,0xdf,0xdb,0xdf,0xdf,0xdf,0xdf,0xdb,0xdf,0xdf,0xb7,0xb7,0xbb,0xdf,0xdf,0xdb,0xdb,0xdf,0xdb,0xdb,0xbb,0x97,0xdb,0xdb,0xdf,0xdb,0xdf,0xdf,0xdf,0xdf,0xdf,0xdf,0xdf,0xdf,0xdf,0xdf,0xdf,0xdf,0xdf,0xdf,0xdf,0xdf,0xdf,0xdf,0xdf,0xdf,0xdf,0xdf,0xdf,0xdf,0xdf,0xdf,0xdf,0xdf,0xdf,0xdf,0xdf,0xdf,0xdf,0xdf
		,0xdf,0xdf,0xdf,0xdf,0xdf,0xdf,0xdf,0xdf,0xdf,0xdf,0xdf,0xdf,0xdf,0xdf,0xdf,0xdf,0xdf,0xdf,0xdf,0xdf,0xdf,0xdf,0xdf,0xdf,0xdf,0xdf,0xdf,0xdf,0xdf,0xdf,0xdf,0xdf,0xdf,0xdf,0xdf,0xdf,0xdf,0xdf,0xdf,0xdb,0x97,0xbb,0xbb,0xdf,0xdb,0xdb,0xdb,0xdf,0xdb,0xdb,0xdb,0xb7,0xbb,0xdf,0xdf,0xdf,0xdf,0xdf,0xdf,0xdf,0xdf,0xdf,0xdf,0xdf,0xdb,0xdf,0xdf,0xdf,0xdf,0xdf,0xdf,0xdf,0xdf,0xdf,0xdf,0xdf,0xdf,0xdf,0xdf,0xdf,0xdf,0xdf,0xdf,0xdf,0xdf,0xdf,0xdf,0xdf,0xdf,0xdf
		,0xdf,0xff,0xdf,0xdf,0xdf,0xdf,0xdf,0xdf,0xdf,0xdf,0xdf,0xdf,0xdf,0xdf,0xdf,0xdf,0xdf,0xdf,0xdf,0xdf,0xdf,0xdf,0xdf,0xdf,0xdf,0xdf,0xdf,0xdf,0xdf,0xdf,0xdf,0xdf,0xdf,0xdf,0xdf,0xdf,0xdf,0xdf,0xdf,0xbb,0xbb,0xbb,0xdb,0xdf,0xdb,0xdb,0xdf,0xdb,0xdf,0xdf,0xdf,0xbb,0xbb,0xdf,0xdf,0xdf,0xdf,0xdf,0xdf,0xdf,0xdf,0xdf,0xff,0xdf,0xdf,0xdf,0xdf,0xdf,0xdf,0xdf,0xdf,0xdf,0xdf,0xdf,0xdf,0xdf,0xdf,0xdf,0xdf,0xdf,0xdf,0xdf,0xdf,0xdf,0xdf,0xff,0xdf,0xdf,0xdf,0xdf
		,0xdf,0xff,0xdf,0xdf,0xdf,0xdf,0xdf,0xdf,0xdf,0xff,0xdf,0xdf,0xdf,0xdf,0xdf,0xdf,0xdf,0xdf,0xdf,0xdf,0xdf,0xdf,0xdf,0xdf,0xdf,0xdf,0xdf,0xdf,0xdf,0xdf,0xdf,0xdf,0xdf,0xdf,0xdf,0xdf,0xdf,0xdf,0xdb,0xb7,0xdb,0xdf,0xbb,0xdb,0xdb,0xdf,0xdf,0xdf,0xdf,0xdf,0xdf,0xdf,0xbb,0xdb,0xdf,0xdf,0xdf,0xdf,0xff,0xdf,0xdf,0xdf,0xdf,0xdf,0xdf,0xdf,0xdf,0xdf,0xdf,0xdf,0xdf,0xdf,0xdf,0xdf,0xdf,0xdf,0xdf,0xdf,0xdf,0xdf,0xdf,0xdf,0xdf,0xdf,0xdf,0xff,0xdf,0xdf,0xdf,0xdf
		,0xff,0xdf,0xdf,0xdf,0xdf,0xdf,0xdf,0xdf,0xdf,0xff,0xdf,0xdf,0xdf,0xdf,0xdf,0xdf,0xdf,0xdf,0xdf,0xdf,0xdf,0xdf,0xdf,0xdf,0xdf,0xdf,0xdf,0xdf,0xdf,0xdf,0xdf,0xdf,0xdf,0xdf,0xdf,0xdf,0xdf,0xdf,0xbb,0xdb,0xdf,0xdf,0xdb,0xdf,0xdf,0xdf,0xdf,0xdf,0xdf,0xdf,0xdf,0xdf,0xdb,0xb7,0xdb,0xdf,0xff,0xdf,0xdf,0xdf,0xdf,0xff,0xdf,0xdf,0xdf,0xdf,0xff,0xdf,0xdf,0xdf,0xdf,0xdf,0xdf,0xdf,0xdf,0xdf,0xdf,0xdf,0xdf,0xdf,0xdf,0xdf,0xdf,0xff,0xdf,0xdf,0xdf,0xdf,0xdf,0xdf
		,0xff,0xff,0xff,0xdf,0xdf,0xdf,0xdf,0xdf,0xdf,0xff,0xdf,0xdf,0xdf,0xdf,0xdf,0xdf,0xdf,0xdf,0xdf,0xdf,0xdf,0xdf,0xdf,0xdf,0xdf,0xdf,0xdf,0xdf,0xdf,0xdf,0xdf,0xdf,0xff,0xdf,0xdf,0xdf,0xdf,0xdb,0xdb,0xdf,0xdf,0xdf,0xdf,0xdf,0xdf,0xff,0xdf,0xdf,0xdf,0xdf,0xdf,0xdf,0xdf,0xdb,0xbb,0xdf,0xdf,0xdf,0xdf,0xff,0xff,0xdf,0xdf,0xdf,0xdf,0xff,0xff,0xff,0xff,0xdf,0xdf,0xdf,0xdf,0xdf,0xdf,0xdf,0xdf,0xdf,0xdf,0xdf,0xdf,0xff,0xff,0xff,0xdf,0xdf,0xdf,0xdf,0xdf,0xdf
		,0xff,0xff,0xff,0xdf,0xdf,0xdf,0xdf,0xdf,0xdf,0xff,0xdf,0xdf,0xff,0xff,0xdf,0xdf,0xdf,0xdf,0xdf,0xdf,0xdf,0xdf,0xdf,0xff,0xff,0xdf,0xdf,0xdf,0xdf,0xdf,0xdf,0xdf,0xff,0xff,0xdf,0xdf,0xdf,0xbb,0xdf,0xdf,0xdf,0xdf,0xdf,0xdf,0xff,0xff,0xdf,0xdf,0xff,0xdf,0xdf,0xdf,0xdf,0xdf,0xdf,0xbb,0xdf,0xdf,0xff,0xdf,0xdf,0xdf,0xdf,0xdf,0xdf,0xdf,0xdf,0xff,0xdf,0xdf,0xdf,0xdf,0xdf,0xdf,0xdf,0xdf,0xdf,0xdf,0xdf,0xff,0xff,0xff,0xff,0xff,0xdf,0xdf,0xdf,0xdf,0xdf,0xdf
		,0xdf,0xdf,0xff,0xdf,0xdf,0xdf,0xdf,0xdf,0xff,0xff,0xff,0xff,0xff,0xff,0xdf,0xdf,0xdf,0xdf,0xdf,0xdf,0xdf,0xdf,0xdf,0xdf,0xff,0xdf,0xdf,0xdf,0xdf,0xdf,0xdf,0xdf,0xdf,0xff,0xff,0xff,0xdb,0xdf,0xdf,0xdf,0xdf,0xdf,0xdf,0xff,0xff,0xff,0xff,0xff,0xdf,0xdf,0xdf,0xdf,0xdf,0xdf,0xdf,0xdf,0xbb,0xdf,0xff,0xdf,0xdf,0xdf,0xdf,0xdf,0xff,0xdf,0xdf,0xdf,0xdf,0xdf,0xdf,0xdf,0xdf,0xdf,0xdf,0xdf,0xdf,0xdf,0xff,0xff,0xff,0xff,0xdf,0xff,0xff,0xdf,0xdf,0xff,0xff,0xdf
		,0xff,0xdf,0xff,0xff,0xff,0xdf,0xdf,0xdf,0xff,0xff,0xff,0xff,0xff,0xff,0xff,0xdf,0xdf,0xdf,0xdf,0xdf,0xdf,0xdf,0xdf,0xdf,0xff,0xdf,0xdf,0xdf,0xdf,0xdf,0xdf,0xdf,0xdf,0xdf,0xff,0xdf,0xdb,0xdf,0xdf,0xdf,0xdf,0xdf,0xdf,0xff,0xff,0xff,0xff,0xdf,0xdf,0xdf,0xff,0xdf,0xdf,0xdf,0xdf,0xdf,0xdf,0xbb,0xdf,0xff,0xdb,0xdf,0xdf,0xff,0xff,0xdf,0xdf,0xdf,0xdf,0xdf,0xdf,0xdf,0xdf,0xdf,0xdf,0xdf,0xdf,0xff,0xff,0xff,0xff,0xff,0xdf,0xdf,0xdf,0xdf,0xdf,0xdf,0xdf,0xdf
		,0xff,0xff,0xff,0xff,0xff,0xdf,0xdf,0xdf,0xff,0xff,0xff,0xff,0xff,0xff,0xff,0xdf,0xdf,0xdf,0xdf,0xdf,0xdf,0xdf,0xdf,0xdf,0xdf,0xdf,0xdf,0xdf,0xdf,0xdf,0xdf,0xdf,0xdf,0xdf,0xdf,0xbb,0xdf,0xff,0xdf,0xdf,0xdf,0xdf,0xdf,0xff,0xff,0xff,0xff,0xdf,0xdf,0xdf,0xdf,0xdf,0xdf,0xdf,0xdf,0xff,0xff,0xdf,0xbb,0xdb,0xdb,0xdf,0xff,0xdf,0xff,0xff,0xdf,0xdf,0xdf,0xdf,0xdf,0xdf,0xdf,0xdf,0xdf,0xdf,0xff,0xff,0xff,0xff,0xff,0xff,0xdf,0xdf,0xdf,0xdf,0xdf,0xff,0xff,0xff
		,0xff,0xff,0xff,0xff,0xff,0xff,0xdf,0xdf,0xdf,0xff,0xff,0xff,0xff,0xff,0xdf,0xdf,0xdf,0xdf,0xdf,0xdf,0xdf,0xdf,0xdf,0xff,0xdf,0xdf,0xdf,0xdf,0xdf,0xdf,0xff,0xdf,0xdf,0xdb,0xbb,0xdb,0xdf,0xdf,0xff,0xdf,0xdf,0xdf,0xdf,0xff,0xff,0xff,0xff,0xdf,0xdf,0xdf,0xdf,0xdf,0xdf,0xdf,0xff,0xff,0xff,0xdf,0xdf,0xdb,0xdf,0xff,0xff,0xff,0xff,0xff,0xdf,0xdf,0xdf,0xdf,0xdf,0xdf,0xdf,0xdf,0xdf,0xdf,0xff,0xff,0xff,0xff,0xff,0xdf,0xff,0xdf,0xdf,0xdf,0xff,0xff,0xff,0xff
		,0xff,0xff,0xff,0xff,0xff,0xff,0xff,0xdf,0xdf,0xff,0xff,0xff,0xff,0xff,0xff,0xff,0xdf,0xdf,0xdf,0xdf,0xdf,0xdf,0xdf,0xff,0xdf,0xdf,0xdf,0xdf,0xdf,0xdf,0xff,0xff,0xff,0xdf,0xdb,0xdf,0xdf,0xdf,0xff,0xff,0xdf,0xdf,0xdf,0xdf,0xff,0xff,0xdf,0xdf,0xdf,0xdf,0xff,0xdf,0xdf,0xff,0xff,0xff,0xff,0xdf,0xff,0xff,0xff,0xff,0xff,0xff,0xff,0xdf,0xdf,0xdf,0xdf,0xdf,0xdf,0xdf,0xdf,0xdf,0xdf,0xff,0xff,0xff,0xff,0xff,0xdf,0xdf,0xdf,0xff,0xdf,0xff,0xff,0xff,0xff,0xff
		,0xdf,0xff,0xff,0xff,0xff,0xff,0xff,0xdf,0xdf,0xff,0xff,0xff,0xff,0xff,0xff,0xff,0xdf,0xff,0xdf,0xdf,0xdf,0xdf,0xdf,0xdf,0xdf,0xdf,0xdf,0xdf,0xdf,0xdf,0xff,0xff,0xff,0xff,0xff,0xff,0xff,0xdf,0xdf,0xdf,0xff,0xdf,0xdf,0xdf,0xff,0xdf,0xdf,0xdf,0xdf,0xdf,0xff,0xdf,0xff,0xff,0xff,0xff,0xff,0xff,0xff,0xff,0xff,0xff,0xff,0xdf,0xdf,0xdf,0xff,0xdf,0xdf,0xdf,0xdf,0xdf,0xdf,0xdf,0xdf,0xff,0xff,0xff,0xff,0xff,0xdf,0xdf,0xdf,0xdf,0xdf,0xff,0xff,0xff,0xff,0xdf
		,0xdf,0xdf,0xff,0xff,0xff,0xff,0xff,0xdf,0xdf,0xff,0xff,0xff,0xff,0xff,0xff,0xff,0xff,0xdf,0xdf,0xdf,0xdf,0xdf,0xdf,0xdf,0xdf,0xdf,0xdf,0xdf,0xdf,0xdf,0xdf,0xdf,0xff,0xff,0xff,0xff,0xff,0xff,0xff,0xdf,0xdf,0xdf,0xdf,0xdf,0xdf,0xdf,0xdf,0xdf,0xdf,0xff,0xff,0xdf,0xff,0xff,0xff,0xff,0xff,0xff,0xff,0xff,0xff,0xff,0xdf,0xdf,0xff,0xff,0xff,0xdf,0xdf,0xdf,0xdf,0xdf,0xdf,0xdf,0xff,0xff,0xff,0xff,0xff,0xff,0xff,0xdf,0xdf,0xdf,0xff,0xff,0xff,0xff,0xff,0xdf
		,0xdf,0xdf,0xff,0xff,0xff,0xff,0xff,0xdf,0xdf,0xff,0xdf,0xff,0xff,0xff,0xff,0xff,0xff,0xdf,0xdf,0xdf,0xdf,0xdf,0xdf,0xdf,0xdf,0xdf,0xdf,0xdf,0xdf,0xdf,0xdf,0xdf,0xff,0xff,0xff,0xff,0xff,0xff,0xff,0xdf,0xdf,0xdf,0xdf,0xdf,0xdf,0xdf,0xdf,0xdf,0xff,0xff,0xff,0xdf,0xff,0xff,0xff,0xff,0xff,0xff,0xff,0xff,0xdf,0xff,0xff,0xdf,0xff,0xff,0xff,0xdf,0xdf,0xdf,0xdf,0xdf,0xdf,0xdf,0xff,0xff,0xff,0xff,0xff,0xdf,0xdf,0xdf,0xdf,0xff,0xdf,0xff,0xff,0xff,0xff,0xff
		,0xdf,0xdf,0xff,0xff,0xff,0xff,0xff,0xff,0xff,0xff,0xff,0xff,0xff,0xff,0xff,0xff,0xff,0xff,0xdf,0xdf,0xdf,0xdf,0xdf,0xdf,0xdf,0xdf,0xdf,0xdf,0xdf,0xdf,0xdf,0xdf,0xff,0xff,0xff,0xff,0xff,0xdf,0xff,0xff,0xff,0xdf,0xdf,0xdf,0xdf,0xdf,0xdf,0xdf,0xff,0xff,0xff,0xdf,0xff,0xff,0xff,0xff,0xdf,0xff,0xff,0xdf,0xff,0xff,0xff,0xff,0xff,0xff,0xff,0xdf,0xdf,0xdf,0xdf,0xdf,0xff,0xdf,0xdf,0xdf,0xff,0xff,0xff,0xff,0xdf,0xdf,0xdf,0xff,0xff,0xff,0xff,0xff,0xff,0xff
		,0xdb,0xdf,0xdf,0xff,0xff,0xff,0xff,0xff,0xff,0xff,0xff,0xff,0xff,0xff,0xff,0xff,0xff,0xff,0xff,0xdf,0xdf,0xdf,0xdf,0xdf,0xdf,0xdf,0xdf,0xdf,0xdf,0xdf,0xdf,0xdf,0xff,0xff,0xff,0xff,0xff,0xff,0xff,0xdf,0xdf,0xdf,0xdf,0xdf,0xdf,0xdf,0xdf,0xff,0xff,0xff,0xdf,0xdf,0xff,0xff,0xff,0xff,0xff,0xff,0xdf,0xdf,0xff,0xff,0xff,0xff,0xff,0xff,0xdf,0xdf,0xdf,0xdf,0xdf,0xdf,0xdf,0xdf,0xdf,0xdf,0xdf,0xff,0xff,0xff,0xff,0xdf,0xdf,0xff,0xff,0xff,0xff,0xff,0xff,0xff
		,0xdb,0xdf,0xff,0xff,0xff,0xff,0xff,0xff,0xff,0xff,0xff,0xff,0xff,0xff,0xff,0xff,0xff,0xff,0xff,0xdf,0xdf,0xdf,0xdf,0xdf,0xdf,0xdf,0xdf,0xdf,0xdf,0xdf,0xdf,0xdf,0xff,0xff,0xff,0xff,0xff,0xff,0xff,0xdf,0xdf,0xdf,0xdf,0xdf,0xdf,0xdf,0xff,0xdf,0xff,0xff,0xdf,0xdf,0xff,0xff,0xff,0xff,0xff,0xff,0xff,0xff,0xff,0xff,0xff,0xff,0xff,0xff,0xdf,0xdf,0xdf,0xdf,0xdf,0xdf,0xdf,0xdf,0xff,0xdf,0xdf,0xff,0xff,0xff,0xff,0xff,0xff,0xff,0xff,0xff,0xff,0xff,0xff,0xff
		,0xbb,0xdf,0xdf,0xff,0xff,0xff,0xff,0xff,0xff,0xff,0xff,0xff,0xff,0xff,0xff,0xff,0xff,0xff,0xff,0xff,0xdf,0xdf,0xdf,0xdf,0xdf,0xdf,0xdf,0xdf,0xdf,0xdf,0xdf,0xdf,0xff,0xff,0xff,0xff,0xff,0xff,0xff,0xff,0xff,0xdf,0xdf,0xdf,0xdf,0xdf,0xff,0xff,0xff,0xff,0xff,0xdf,0xff,0xff,0xff,0xff,0xff,0xff,0xff,0xff,0xff,0xff,0xff,0xff,0xff,0xdf,0xdf,0xdf,0xdf,0xdf,0xdf,0xdf,0xdf,0xdf,0xff,0xdf,0xdf,0xff,0xdf,0xff,0xff,0xff,0xff,0xff,0xff,0xff,0xff,0xff,0xff,0xff
		,0xbb,0xdb,0xdf,0xff,0xff,0xff,0xff,0xff,0xff,0xff,0xff,0xff,0xff,0xff,0xff,0xff,0xff,0xff,0xff,0xff,0xdf,0xdf,0xdf,0xdf,0xdf,0xdf,0xdf,0xdf,0xdf,0xdf,0xdf,0xdf,0xff,0xff,0xff,0xff,0xff,0xff,0xff,0xff,0xff,0xff,0xdf,0xdf,0xdf,0xdf,0xdf,0xff,0xff,0xff,0xff,0xdf,0xff,0xff,0xff,0xff,0xdf,0xdf,0xff,0xff,0xff,0xff,0xff,0xff,0xff,0xdf,0xdf,0xdf,0xdf,0xdf,0xdf,0xdf,0xdf,0xdf,0xff,0xff,0xdf,0xff,0xdf,0xdf,0xdf,0xff,0xff,0xff,0xff,0xff,0xff,0xff,0xff,0xff
		,0xdb,0xdb,0xdf,0xdf,0xff,0xff,0xff,0xff,0xff,0xff,0xff,0xff,0xff,0xff,0xff,0xff,0xdf,0xdf,0xff,0xff,0xff,0xff,0xff,0xff,0xdf,0xdf,0xdf,0xdf,0xdf,0xdf,0xdf,0xdf,0xff,0xff,0xff,0xff,0xff,0xff,0xff,0xff,0xff,0xdf,0xdf,0xdf,0xdf,0xdf,0xdf,0xdf,0xff,0xff,0xff,0xdf,0xff,0xff,0xff,0xff,0xdf,0xff,0xff,0xff,0xff,0xff,0xff,0xff,0xdf,0xff,0xdf,0xdf,0xdf,0xdf,0xdf,0xff,0xdf,0xdf,0xdf,0xff,0xff,0xdf,0xdf,0xdf,0xff,0xff,0xdf,0xff,0xff,0xff,0xff,0xff,0xff,0xff
		,0xdb,0xdb,0xdf,0xdf,0xff,0xff,0xff,0xff,0xff,0xff,0xff,0xff,0xff,0xff,0xff,0xff,0xdf,0xff,0xff,0xff,0xff,0xff,0xff,0xff,0xdf,0xdf,0xdf,0xdf,0xdf,0xdf,0xdf,0xdf,0xff,0xff,0xff,0xff,0xff,0xff,0xff,0xff,0xff,0xdf,0xdf,0xdf,0xdf,0xff,0xff,0xff,0xff,0xff,0xff,0xdf,0xff,0xff,0xff,0xff,0xdf,0xdf,0xdf,0xff,0xff,0xff,0xff,0xff,0xdf,0xff,0xdf,0xdf,0xdf,0xdf,0xff,0xff,0xff,0xdf,0xdf,0xff,0xdf,0xdf,0xdf,0xdf,0xff,0xff,0xff,0xff,0xff,0xff,0xff,0xff,0xff,0xff
		,0xdb,0xbb,0xdf,0xdf,0xdf,0xff,0xff,0xff,0xff,0xff,0xff,0xff,0xff,0xff,0xff,0xff,0xff,0xff,0xff,0xff,0xff,0xff,0xff,0xff,0xff,0xdf,0xdf,0xdf,0xdf,0xdf,0xdf,0xdf,0xff,0xff,0xff,0xff,0xff,0xff,0xff,0xff,0xff,0xdf,0xdf,0xdf,0xdf,0xff,0xdf,0xff,0xff,0xff,0xff,0xff,0xdf,0xff,0xff,0xdf,0xdf,0xdf,0xdf,0xff,0xff,0xff,0xff,0xff,0xdf,0xdf,0xdf,0xdf,0xdf,0xff,0xff,0xff,0xff,0xff,0xff,0xff,0xff,0xff,0xdf,0xff,0xff,0xff,0xff,0xff,0xff,0xff,0xff,0xff,0xff,0xff
		,0xdf,0xbb,0xdf,0xdf,0xdf,0xdf,0xff,0xff,0xff,0xff,0xff,0xff,0xff,0xff,0xff,0xff,0xff,0xff,0xff,0xff,0xff,0xff,0xff,0xff,0xdf,0xdf,0xdf,0xdf,0xdf,0xdf,0xdf,0xdf,0xdf,0xff,0xff,0xff,0xff,0xff,0xff,0xff,0xff,0xdf,0xdf,0xdf,0xdf,0xdf,0xdf,0xff,0xff,0xff,0xff,0xdf,0xdf,0xff,0xff,0xdf,0xdf,0xdf,0xff,0xff,0xff,0xff,0xff,0xdf,0xdf,0xff,0xdf,0xdf,0xdf,0xff,0xff,0xff,0xff,0xff,0xff,0xff,0xff,0xdf,0xdf,0xff,0xff,0xff,0xff,0xff,0xff,0xff,0xff,0xff,0xff,0xff
};
/* USER CODE END PV */

void SystemClock_Config(void);
/* USER CODE BEGIN PFP */
uint16_t CRC16_2(uint8_t*, uint8_t);
uint16_t MixedColor(uint8_t, uint8_t, uint8_t);
void Render_Dashboard(void);
void Render_Information(void);
void ILI9341_Draw_Small_Image(const uint16_t*, uint16_t, uint16_t, uint16_t, uint16_t);
/* USER CODE END PFP */

int main(void)
{

  /* USER CODE BEGIN 1 */
	char str[50];
	uint8_t cmdBuffer[3];
	uint8_t dataBuffer[8];
  /* USER CODE END 1 */

  /* Enable the CPU Cache */

  /* Enable I-Cache---------------------------------------------------------*/
  SCB_EnableICache();

  /* Enable D-Cache---------------------------------------------------------*/
  SCB_EnableDCache();

  /* MCU Configuration--------------------------------------------------------*/

  /* Reset of all peripherals, Initializes the Flash interface and the Systick. */
  HAL_Init();

  /* Configure the system clock */
  SystemClock_Config();

  /* Initialize all configured peripherals */
  MX_GPIO_Init();
  MX_SPI5_Init();
  MX_RNG_Init();
  MX_TIM1_Init();
  MX_I2C1_Init();
  MX_USART3_UART_Init();
  /* USER CODE BEGIN 2 */
  sprintf(str, "\n\rAM2320 I2C DEMO Starting...\n\r");
  HAL_UART_Transmit(&huart3, (uint8_t*)str, strlen(str), 200);

  cmdBuffer[0] = 0x03;
  cmdBuffer[1] = 0x00;
  cmdBuffer[2] = 0x04;

  ILI9341_Init();
  ILI9341_Set_Rotation(SCREEN_HORIZONTAL_1);
  ILI9341_Fill_Screen(WHITE);
//  Render_Dashboard();
  /* USER CODE END 2 */

  /* Infinite loop */
  while (1)
  {

    /* USER CODE BEGIN 3 */
	sprintf(str, "Temp = %4.1f\tHumidity = %4.1f\n\r", t, h);
	while(__HAL_UART_GET_FLAG(&huart3, UART_FLAG_TC) == 0) {}
	HAL_UART_Transmit(&huart3, (uint8_t*)str, strlen(str), 200);

	HAL_I2C_Master_Transmit(&hi2c1, 0x5c<<1, cmdBuffer, 3, 200);

	HAL_I2C_Master_Transmit(&hi2c1, 0x5c<<1, cmdBuffer, 3, 200);

	HAL_Delay(1);

	HAL_I2C_Master_Receive(&hi2c1, 0x5c<<1, dataBuffer, 8, 200);

	uint16_t Rcrc = dataBuffer[7] << 8;
	Rcrc += dataBuffer[6];

	if (Rcrc == CRC16_2(dataBuffer, 6))
	{
		uint16_t temperature = ((dataBuffer[4] & 0x7F) << 8) + dataBuffer[5];
		t = temperature / 10.0;
		t = (((dataBuffer[4] & 0x80) >> 7) == 1) ? (t * (-1)) : t;

		uint16_t humidity = (dataBuffer[2] << 8) + dataBuffer[3];
		h = humidity / 10.0;

		Render_Dashboard();
	}

	if (TP_Touchpad_Pressed())
	{
		uint16_t x_touch, y_touch;
	    uint16_t pos[2];

	    if (TP_Read_Coordinates(pos) == TOUCHPAD_DATA_OK)
	    {
	    	x_touch = pos[0];
	        y_touch = pos[1];

	        uint16_t x_screen = y_touch;
	        uint16_t y_screen = 240 - x_touch;

			if (x_screen > 20 && x_screen < 60 && y_screen > 80 && y_screen < 120)
			{
				r_percent = (r_percent >= 100) ? 0 : r_percent + 10;
				Render_Dashboard();
				HAL_Delay(200);
			}
			else if (x_screen > 20 && x_screen < 60 && y_screen > 130 && y_screen < 170)
			{
				g_percent = (g_percent >= 100) ? 0 : g_percent + 10;
				Render_Dashboard();
				HAL_Delay(200);
			}
			else if (x_screen > 20 && x_screen < 60 && y_screen > 180 && y_screen < 220) {
				b_percent = (b_percent >= 100) ? 0 : b_percent + 10;
				Render_Dashboard();
				HAL_Delay(200);
			}
			else if (x_screen > 120 && x_screen < 140 && y_screen > 30 && y_screen < 50) {
				ILI9341_Fill_Screen(WHITE);
				Render_Information();
				HAL_Delay(5000);
				ILI9341_Fill_Screen(WHITE);
			}
	    }
	}
  }
  /* USER CODE END 3 */
}

void SystemClock_Config(void)
{
  RCC_OscInitTypeDef RCC_OscInitStruct = {0};
  RCC_ClkInitTypeDef RCC_ClkInitStruct = {0};

  /** Configure the main internal regulator output voltage
  */
  __HAL_RCC_PWR_CLK_ENABLE();
  __HAL_PWR_VOLTAGESCALING_CONFIG(PWR_REGULATOR_VOLTAGE_SCALE1);

  /** Initializes the RCC Oscillators according to the specified parameters
  * in the RCC_OscInitTypeDef structure.
  */
  RCC_OscInitStruct.OscillatorType = RCC_OSCILLATORTYPE_HSI;
  RCC_OscInitStruct.HSIState = RCC_HSI_ON;
  RCC_OscInitStruct.HSICalibrationValue = RCC_HSICALIBRATION_DEFAULT;
  RCC_OscInitStruct.PLL.PLLState = RCC_PLL_ON;
  RCC_OscInitStruct.PLL.PLLSource = RCC_PLLSOURCE_HSI;
  RCC_OscInitStruct.PLL.PLLM = 8;
  RCC_OscInitStruct.PLL.PLLN = 200;
  RCC_OscInitStruct.PLL.PLLP = RCC_PLLP_DIV2;
  RCC_OscInitStruct.PLL.PLLQ = 9;
  RCC_OscInitStruct.PLL.PLLR = 2;
  if (HAL_RCC_OscConfig(&RCC_OscInitStruct) != HAL_OK)
  {
    Error_Handler();
  }

  /** Activate the Over-Drive mode
  */
  if (HAL_PWREx_EnableOverDrive() != HAL_OK)
  {
    Error_Handler();
  }

  /** Initializes the CPU, AHB and APB buses clocks
  */
  RCC_ClkInitStruct.ClockType = RCC_CLOCKTYPE_HCLK|RCC_CLOCKTYPE_SYSCLK
                              |RCC_CLOCKTYPE_PCLK1|RCC_CLOCKTYPE_PCLK2;
  RCC_ClkInitStruct.SYSCLKSource = RCC_SYSCLKSOURCE_PLLCLK;
  RCC_ClkInitStruct.AHBCLKDivider = RCC_SYSCLK_DIV1;
  RCC_ClkInitStruct.APB1CLKDivider = RCC_HCLK_DIV4;
  RCC_ClkInitStruct.APB2CLKDivider = RCC_HCLK_DIV2;

  if (HAL_RCC_ClockConfig(&RCC_ClkInitStruct, FLASH_LATENCY_6) != HAL_OK)
  {
    Error_Handler();
  }
}

/* USER CODE BEGIN 4 */
uint16_t CRC16_2(uint8_t *ptr, uint8_t length)
{
	uint16_t crc = 0xFFFF;
	uint8_t s = 0x00;

	while(length--)
	{
		crc ^= *ptr++;
		for(s=0; s<8; s++)
		{
			if((crc & 0x01) != 0)
			{
				crc >>= 1;
				crc ^= 0xA001;
			} else crc >>= 1;
		}
	}

	return crc;
}

uint16_t MixedColor(uint8_t r, uint8_t g, uint8_t b)
{
	return (((r_percent * 31 / 100) << 11) | ((g_percent * 63 / 100) << 5) | ((b_percent * 31 / 100)));
}

void ILI9341_Draw_Small_Image(const uint16_t* image, uint16_t x, uint16_t y, uint16_t width, uint16_t height)
{
    ILI9341_Set_Address(x, y, x + width - 1, y + height - 1);

    for (uint32_t i = 0; i < (width * height); i++) {
        uint16_t color = image[i];

        uint8_t data[] = { (color >> 8) & 0xFF, color & 0xFF };
        ILI9341_Write_Data(data[0]);
        ILI9341_Write_Data(data[1]);
    }
}

void Render_Dashboard() {
    uint16_t mixed_color = MixedColor(r_percent, g_percent, b_percent);

    // Mixed Color
    ILI9341_Draw_Filled_Circle(130, 40, 20, mixed_color);

    // Red
    ILI9341_Draw_Filled_Circle(40, 100, 20, RED);
    ILI9341_Draw_Filled_Rectangle_Coord(80, 90, 200, 115, LIGHT_RED);
    ILI9341_Draw_Filled_Rectangle_Coord(80, 90, 80 + (r_percent * 120 / 100), 115, RED);

    // Green
    ILI9341_Draw_Filled_Circle(40, 150, 20, GREEN);
    ILI9341_Draw_Filled_Rectangle_Coord(80, 140, 200, 165, LIGHT_GREEN);
    ILI9341_Draw_Filled_Rectangle_Coord(80, 140, 80 + (g_percent * 120 / 100), 165, GREEN);

    // Blue
    ILI9341_Draw_Filled_Circle(40, 200, 20, BLUE);
    ILI9341_Draw_Filled_Rectangle_Coord(80, 190, 200, 215, LIGHT_BLUE);
    ILI9341_Draw_Filled_Rectangle_Coord(80, 190, 80 + (b_percent * 120 / 100), 215, BLUE);

    char buff[10];
    sprintf(buff, "%4.1fC", t);
    ILI9341_Draw_Text(buff, 30, 30, BLACK, 2, WHITE);
    sprintf(buff, "%4.1f%%RH", h);
    ILI9341_Draw_Text(buff, 165, 30, BLACK, 2, WHITE);

    sprintf(buff, "%d%%  ", r_percent);
    ILI9341_Draw_Text(buff, 205, 95, BLACK, 2, WHITE);
    sprintf(buff, "%d%%  ", g_percent);
    ILI9341_Draw_Text(buff, 205, 145, BLACK, 2, WHITE);
    sprintf(buff, "%d%%  ", b_percent);
    ILI9341_Draw_Text(buff, 205, 195, BLACK, 2, WHITE);
}

void Render_Information()
{
	uint16_t mixed_color = MixedColor(r_percent, g_percent, b_percent);

	ILI9341_Draw_Small_Image((uint16_t*)profile, 10, 50, 90, 120);

	char buff[20];
	sprintf(buff, "Group No.5026");
	ILI9341_Draw_Text(buff, 110, 50, mixed_color, 2, WHITE);

	sprintf(buff, "Chatnarint");
	ILI9341_Draw_Text(buff, 110, 80, mixed_color, 2, WHITE);

	sprintf(buff, "Boonsaeng");
	ILI9341_Draw_Text(buff, 110, 110, mixed_color, 2, WHITE);

	sprintf(buff, "67015026");
	ILI9341_Draw_Text(buff, 110, 140, mixed_color, 2, WHITE);
}
/* USER CODE END 4 */

void Error_Handler(void)
{
  __disable_irq();
  while (1)
  {
  }
}
